AUTOSAR XML (schema 00046)
standard types defined: uint16, uint32, uint8, boolean
package /Constants
  14 x constant specification:
    Init_OnOffNull2: value-spec=0
    Init_ReducedGuardDStat: value-spec=0
    Init_RequestStatusType: value-spec=0
    Init_TrnNtrlTowCmdActl: value-spec=0
    InitVal_doorAjarStatus: value-spec=[Index_0:DoorAjarStatus_AJAR, Index_1:DoorAjarStatus_AJAR, Index_2:DoorAjarStatus_AJAR, Index_3:DoorAjarStatus_AJAR, Index_4:DoorAjarStatus_AJAR, Index_5:DoorAjarStatus_AJAR, Index_6:DoorAjarStatus_AJAR, Index_7:DoorAjarStatus_AJAR, Index_8:DoorAjarStatus_AJAR, Index_9:DoorAjarStatus_AJAR]
    InitVal_exteriorDoorHandleStatus: value-spec=[index_0:ExteriorDoorHandleStatus_LOCK_STATUS_FAULTY, index_1:ExteriorDoorHandleStatus_LOCK_STATUS_FAULTY, index_2:ExteriorDoorHandleStatus_LOCK_STATUS_FAULTY, index_3:ExteriorDoorHandleStatus_LOCK_STATUS_FAULTY, index_4:ExteriorDoorHandleStatus_LOCK_STATUS_FAULTY, index_5:ExteriorDoorHandleStatus_LOCK_STATUS_FAULTY, index_6:ExteriorDoorHandleStatus_LOCK_STATUS_FAULTY, index_7:ExteriorDoorHandleStatus_LOCK_STATUS_FAULTY, index_8:ExteriorDoorHandleStatus_LOCK_STATUS_FAULTY, index_9:ExteriorDoorHandleStatus_LOCK_STATUS_FAULTY]
    InitVal_exteriorLockEventCount: value-spec=1
    InitVal_exteriorVehicleLockStatus: value-spec=0
    InitVal_lastLockUnlockRequestor: value-spec=0
    InitVal_PerimeterAlrmStat: value-spec=0
    InitVal_VehPwMdeStatGrp: value-spec={short-label=InitVal_VehPwMdeStatGrp, fields=[VehPwMdeStat:VPM20, VehPwMdeStatQlfr:VehPwMdeStatQlfr_NO_DATA_EXISTS]}
    InitVal_VSUActvtyStat: value-spec=0
    InitVal_VSUInhbtStat: value-spec={short-label=InitVal_VSUInhbtStat, fields=VSUInhbtStat:VSUInhbtStat_VSU_NO_INHIBIT}
    InitValue_IntrusionInclinationStatus: value-spec=[fields=[SensorId:sensorIdEnum_INCLINATION, SensorState:SensorStateEnum_UNKNOWN, SensorModuleHealthStat:SensorModuleHealthEnum_NOT_AVAILABLE, SensorTriggeredData:SensorTriggeredDataEnum_NOT_TRIGGERED], fields=[SensorId:sensorIdEnum_INTRUSION, SensorState:SensorStateEnum_UNKNOWN, SensorModuleHealthStat:SensorModuleHealthEnum_NOT_AVAILABLE, SensorTriggeredData:SensorTriggeredDataEnum_NOT_TRIGGERED]]
package /DataConstraints
  range boolean_DataConstr6: raw 0..1
package /DataTypeMappings
  7 x data type mapping set:
    DataTypeMappingSet_AutoVehicleShutdownServiceProvider
      data-type-maps:
        application-data-type=AVSConfigType, implementation-data-type=uint8
        application-data-type=AVSShutdownLimitInfo, implementation-data-type=uint8
        application-data-type=AVSWarningInfo, implementation-data-type=uint8
        application-data-type=FeatureID, implementation-data-type=uint8
        application-data-type=IdleShutdownTimeRange, implementation-data-type=uint8
        application-data-type=InhibitRequestType, implementation-data-type=uint8
        application-data-type=InhibitStatus, implementation-data-type=uint8
        application-data-type=RequestStatusType, implementation-data-type=uint8
        application-data-type=UserSelRange, implementation-data-type=uint16
        application-data-type=boolean, implementation-data-type=boolean
    DataTypeMappingSet_DoorService
      data-type-maps:
        application-data-type=AnyDoorAjarStatusEnum, implementation-data-type=uint8
        application-data-type=AudibleLockFeedbackEnum, implementation-data-type=uint8
        application-data-type=DoorAjarStatusArray, implementation-data-type=DoorAjarStatusArray
        application-data-type=DoorCinchStatusArray, implementation-data-type=DoorCinchStatusArray
        application-data-type=DoorFullOpenStatusArray, implementation-data-type=DoorFullOpenStatusArray
        application-data-type=DoorIDBF, implementation-data-type=uint16
        application-data-type=DoorOffStatusArray, implementation-data-type=DoorOffStatusArray
        application-data-type=DoorOpenOperationStatusArray, implementation-data-type=DoorOpenOperationStatusArray
        application-data-type=DoorServiceCapabilityArray, implementation-data-type=DoorServiceCapabilityArray
        application-data-type=EmergencyReleaseSwitchStatusEnum, implementation-data-type=uint8
        application-data-type=ExteriorDoorHandleButtonStatusArray, implementation-data-type=ExteriorDoorHandleButtonStatusArray
        application-data-type=ExteriorDoorHandleStatusArray, implementation-data-type=ExteriorDoorHandleStatusArray
        application-data-type=ExteriorSideDoorCloseLockSwitchStatusArray, implementation-data-type=ExteriorSideDoorCloseLockSwitchStatusArray
        application-data-type=ExteriorSideDoorUnlockReleaseSwitchStatusArray, implementation-data-type=ExteriorSideDoorUnlockReleaseSwitchStatusArray
        application-data-type=ExteriorVehicleLockStatusEnum, implementation-data-type=uint8
        application-data-type=FrunkLatchCommandRequestEnum, implementation-data-type=uint8
        application-data-type=FrunkLatchMotorFaultStatusEnum, implementation-data-type=uint8
        application-data-type=FrunkLatchMotorStatusEnum, implementation-data-type=uint8
        application-data-type=HoodAjarSwitchStatusEnum, implementation-data-type=uint8
        application-data-type=Integer, implementation-data-type=uint8
        application-data-type=InteriorDoorHandleButtonStatusArray, implementation-data-type=InteriorDoorHandleButtonStatusArray
        application-data-type=InteriorDoorHandleStatusArray, implementation-data-type=InteriorDoorHandleStatusArray
        application-data-type=InteriorSideDoorReleaseSwitchStatusArray, implementation-data-type=InteriorSideDoorReleaseSwitchStatusArray
        application-data-type=LatchPositionStatusArray, implementation-data-type=LatchPositionStatusArray
        application-data-type=LockoutProtectionClassEnum, implementation-data-type=uint8
        application-data-type=OneTwoStageBehaviourEnum, implementation-data-type=uint8
        application-data-type=OpenCloseCustomizationStatusArray, implementation-data-type=OpenCloseCustomizationStatusArray
        application-data-type=OverrideAllowedEnum, implementation-data-type=uint8
        application-data-type=PawlSwitchStatusEnum, implementation-data-type=uint8
        application-data-type=ReleaseSwitchStatusEnum, implementation-data-type=uint8
        application-data-type=RequestorTypeClassEnum, implementation-data-type=uint8
        application-data-type=RequestorTypeClassMEnum, implementation-data-type=uint8
        application-data-type=SideDoorSwitchStatusEnum, implementation-data-type=uint8
        application-data-type=TrimInhibitSettingEnum, implementation-data-type=uint8
        application-data-type=TrimSwitchInhibitStatusEnum, implementation-data-type=uint8
        application-data-type=VehicleAreaEnum, implementation-data-type=uint8
    DataTypeMappingSet_IntrusionInclinationServiceProvider
      data-type-maps:
        application-data-type=AlarmState, implementation-data-type=uint8
        application-data-type=CSMTestRequest, implementation-data-type=uint8
        application-data-type=ConfigStatus, implementation-data-type=uint8
        application-data-type=FaultValue, implementation-data-type=uint8
        application-data-type=IntrusionInclinationCapabilityArr, implementation-data-type=IntrusionInclinationCapabilityArr
        application-data-type=IntrusionInclinationIdEnum, implementation-data-type=uint8
        application-data-type=IntrusionInclinationStatusArr, implementation-data-type=IntrusionInclinationStatusArr
        application-data-type=ModeIdEnum, implementation-data-type=uint8
        application-data-type=RearIntrusionStatusStrct, implementation-data-type=RearIntrusionStatusStrct
        application-data-type=SelfTestState, implementation-data-type=uint8
        application-data-type=SensorControlRequest, implementation-data-type=uint8
        application-data-type=SensorModuleHealthEnum, implementation-data-type=uint8
        application-data-type=SensorState, implementation-data-type=uint8
        application-data-type=SensorStateEnum, implementation-data-type=uint8
        application-data-type=SensorTriggeredDataEnum, implementation-data-type=uint8
    DataTypeMappingSet_PerimeterAntiTheftAlarmFeatureApp
      data-type-maps:
        application-data-type=OnOffNull2, implementation-data-type=uint8
        application-data-type=PerimeterAlrmStat, implementation-data-type=uint8
        application-data-type=PrmtrAlrmEvntDStat2, implementation-data-type=uint8
        application-data-type=ReducedGuard, implementation-data-type=uint8
        application-data-type=TrnNtrlTowCmdActl, implementation-data-type=uint8
        application-data-type=VSUActvtyStat, implementation-data-type=uint8
    DataTypeMappingSet_PerimeterAntiTheftAlarmFeatureAppASILB
      data-type-maps:
        application-data-type=VSUInhbtStat, implementation-data-type=VSUInhbtStat
        application-data-type=VSUInhbtStatType, implementation-data-type=uint8
    DataTypeMappingSet_SounderServiceProvider
      data-type-maps:
        application-data-type=HornPatternEnum, implementation-data-type=uint8
        application-data-type=HornStatusEnum, implementation-data-type=uint8
        application-data-type=Repetitions, implementation-data-type=uint16
        application-data-type=SoundPatternEnum, implementation-data-type=uint8
        application-data-type=SounderIdEnum, implementation-data-type=uint8
        application-data-type=SounderRequestEnum, implementation-data-type=uint8
        application-data-type=SounderStatusArr, implementation-data-type=SounderStatusArr
        application-data-type=Time, implementation-data-type=uint16
        application-data-type=customTimeConfigStrct, implementation-data-type=customTimeConfigStrct
        application-data-type=uint16, implementation-data-type=uint16
        application-data-type=uint32, implementation-data-type=uint32
        application-data-type=uint8, implementation-data-type=uint8
    DataTypeMappingSet_TurnLightServiceProvider
      data-type-maps:
        application-data-type=AllFlashActn, implementation-data-type=uint8
        application-data-type=ExteriorLightActuationStatus, implementation-data-type=uint8
        application-data-type=ExteriorLightHealth, implementation-data-type=uint8
        application-data-type=ExteriorLightOnOff, implementation-data-type=uint8
        application-data-type=ExteriorLightPositionEnum, implementation-data-type=uint8
        application-data-type=ExteriorLightPurposeEnum, implementation-data-type=uint8
        application-data-type=ExteriorLightStatus, implementation-data-type=uint8
        application-data-type=ExtrLghtMs, implementation-data-type=uint16
        application-data-type=ExtrLightActionFlash, implementation-data-type=uint8
        application-data-type=FlashPatternEnum, implementation-data-type=uint8
        application-data-type=FlashTSrc, implementation-data-type=uint8
        application-data-type=GlobalStartTime, implementation-data-type=GlobalStartTime
        application-data-type=HazrdLghtStat, implementation-data-type=uint8
        application-data-type=Integer, implementation-data-type=uint8
        application-data-type=Intensity_Adt, implementation-data-type=uint8
        application-data-type=LeFlashActn, implementation-data-type=uint8
        application-data-type=LifeCycMdeDActl, implementation-data-type=uint8
        application-data-type=LightPositionEnum, implementation-data-type=uint8
        application-data-type=LightPurposeEnum, implementation-data-type=uint8
        application-data-type=Priority, implementation-data-type=uint16
        application-data-type=RiFlashActn, implementation-data-type=uint8
        application-data-type=StartTime_Adt, implementation-data-type=uint32
        application-data-type=TellTaleActStrct, implementation-data-type=TellTaleActStrct
        application-data-type=TellTaleId, implementation-data-type=uint8
        application-data-type=TurnDirectionEnum, implementation-data-type=uint8
        application-data-type=TurnIndcnStat, implementation-data-type=uint8
        application-data-type=TurnLightIdEnum, implementation-data-type=uint8
        application-data-type=TurnLightStatusArray, implementation-data-type=TurnLightStatusArray
        application-data-type=VehPwMdeStat, implementation-data-type=uint8
        application-data-type=VehPwMdeStatGrp, implementation-data-type=VehPwMdeStatGrp
        application-data-type=VehPwMdeStatQlfrEnum, implementation-data-type=uint8
        application-data-type=WarningTypeEnum, implementation-data-type=uint8
        application-data-type=boolean, implementation-data-type=boolean
        application-data-type=exteriorLightOnOffFadeEnum, implementation-data-type=uint8
        application-data-type=exteriorLightStatusStrct, implementation-data-type=exteriorLightStatusStrct
package /DataTypeMappingSets
  7 x data type mapping set:
    DataTypeMappingSet_StrtUpStopArbitrator
      data-type-maps:
        application-data-type=AcsyDlyStat, implementation-data-type=uint8
        application-data-type=StrtRqTypeStat, implementation-data-type=uint8
    DataTypeMappingSet_TrailerAlarmServiceConsumer
      data-type-maps:
        application-data-type=TrailerAlarmActivation, implementation-data-type=uint8
        application-data-type=TrailerAlarmFault, implementation-data-type=uint8
        application-data-type=TrailerAlarmTimer, implementation-data-type=uint8
        application-data-type=TrailerAlarmTrigger, implementation-data-type=uint8
    DataTypeMappingSet_TrailerAlarmServiceProvider
      data-type-maps:
        application-data-type=TrailerAlarmActivation, implementation-data-type=uint8
        application-data-type=TrailerAlarmFault, implementation-data-type=uint8
        application-data-type=TrailerAlarmTimer, implementation-data-type=uint8
        application-data-type=TrailerAlarmTrigger, implementation-data-type=uint8
    DataTypeMappingSet_TrailerConnectionAlarmServiceProvider: data-type-map{application-data-type=TrailerConnectionAlarmSetting, implementation-data-type=uint8}
    PerimeterAlrmVehMdeNewTrgEvnt
      data-type-maps:
        application-data-type=Duration, implementation-data-type=uint32
        application-data-type=LifeCycMdeDActl, implementation-data-type=uint8
        application-data-type=PerimeterAlarmEvStackArray, implementation-data-type=PerimeterAlarmEvStackArray
        application-data-type=PerimeterAlarmTmStackArray, implementation-data-type=PerimeterAlarmTmStackArray
        application-data-type=UseCaseId, implementation-data-type=uint32
        application-data-type=DoorAjarStatusEnum, implementation-data-type=uint8
        application-data-type=ExteriorDoorHandleStatusEnum, implementation-data-type=uint8
        application-data-type=SensorIdEnum, implementation-data-type=uint8
        application-data-type=SensorModuleHealthEnum, implementation-data-type=uint8
        application-data-type=SensorStateEnum, implementation-data-type=uint8
        application-data-type=SensorTriggeredDataEnum, implementation-data-type=uint8
        application-data-type=ClimateAirflwSettingArr, implementation-data-type=ClimateAirflwSettingArr
        application-data-type=ClimateAirflwSettingStrct, implementation-data-type=ClimateAirflwSettingStrct
        application-data-type=ClimtZnId, implementation-data-type=uint8
        application-data-type=Spprtd, implementation-data-type=boolean
        application-data-type=ClimtMdeStat, implementation-data-type=boolean
        application-data-type=ClimtSpdLvl, implementation-data-type=uint8
        application-data-type=TrailerConnection, implementation-data-type=uint8
    SounderSrvc
      data-type-maps:
        application-data-type=HornPatternEnum, implementation-data-type=uint8
        application-data-type=HornStatusEnum, implementation-data-type=uint8
        application-data-type=Repetitions, implementation-data-type=uint16
        application-data-type=SoundPatternEnum, implementation-data-type=uint8
        application-data-type=SounderActuationStatusEnum, implementation-data-type=uint8
        application-data-type=SounderHealthEnum, implementation-data-type=uint8
        application-data-type=SounderIdEnum, implementation-data-type=uint8
        application-data-type=SounderStatusArr, implementation-data-type=SounderStatusArr
        application-data-type=SounderStatusStrct, implementation-data-type=SounderStatusStrct
        application-data-type=Time, implementation-data-type=uint16
        application-data-type=boolean, implementation-data-type=boolean
        application-data-type=customTimeConfigStrct, implementation-data-type=customTimeConfigStrct
        application-data-type=uint8, implementation-data-type=uint8
        application-data-type=uint16, implementation-data-type=uint16
        application-data-type=uint32, implementation-data-type=uint32
        application-data-type=SounderRequestEnum, implementation-data-type=uint8
    Timer: data-type-map{application-data-type=TmrCntUnit32, implementation-data-type=uint32}
package /DataTypes
  4 x impl type, all with category=VALUE, base-type=uint8, sw-calibration-access=READ-ONLY, type-emitter=RTE:
    AlarmSoundCfg: compu {0=VEHICLE_HORN, 1=SECURITY_HORN, 2=BBS, 3=BBS_VEHICLE_HORN}
    PerimeterAlrmStat: compu-method=PerimeterAlrmStat, range raw 0..3
    ReducedGuard: compu-method=ReducedGuard, range raw 0..3
    SecurityCfg: compu {0=SECURITYCFG_NONE, 1=SECURITYCFG_BOTH, 2=SECURITYCFG_INCLINATION, 3=SECURITYCFG_INTRUSION, 4=SECURITYCFG_INTRUSION_REAR_INTRUSION, 5=SECURITYCFG_BOTH_REAR_INTRUSION}, range raw 0..5
package /DataTypes/ApplicationDataTypes
  22 x application array data type, all with category=ARRAY:
    ClimateAirflwSettingArr
      element ClimateAirflwSettingArr: category=STRUCTURE, type=ClimateAirflwSettingStrct, array-size-semantics=FIXED-SIZE, max-number-of-elements=19
    DoorAjarStatusArray
      element DoorAjarStatusArray: category=VALUE, type=DoorAjarStatusEnum, array-size-semantics=FIXED-SIZE, max-number-of-elements=10
    DoorCinchStatusArray
      element DoorCinchStatusArray: category=VALUE, type=DoorCinchStatusEnum, array-size-semantics=FIXED-SIZE, max-number-of-elements=10
    DoorFullOpenStatusArray
      element DoorFullOpenStatusArray: category=VALUE, type=DoorFullOpenStatusEnum, array-size-semantics=FIXED-SIZE, max-number-of-elements=10
    DoorOffStatusArray
      element DoorOffStatusArray: category=VALUE, type=DoorOffStatusEnum, array-size-semantics=FIXED-SIZE, max-number-of-elements=10
    DoorOpenOperationStatusArray
      element DoorOpenOperationStatusArray: category=VALUE, type=DoorOpenOperationStatusEnum, array-size-semantics=FIXED-SIZE, max-number-of-elements=10
    DoorServiceCapabilityArray
      element DoorServiceCapabilityArray: category=VALUE, type=DoorServiceCapabilityStatusBF, array-size-semantics=FIXED-SIZE, max-number-of-elements=10
    ExteriorDoorHandleButtonStatusArray
      element ExteriorDoorHandleButtonStatusArray: category=VALUE, type=SideDoorSwitchStatusEnum, array-size-semantics=FIXED-SIZE, max-number-of-elements=10
    ExteriorDoorHandleStatusArray
      element ExteriorDoorHandleStatusArray: category=VALUE, type=ExteriorDoorHandleStatusEnum, array-size-semantics=FIXED-SIZE, max-number-of-elements=10
    ExteriorSideDoorCloseLockSwitchStatusArray
      element ExteriorSideDoorCloseLockSwitchStatusArray: category=VALUE, type=SideDoorSwitchStatusEnum, array-size-semantics=FIXED-SIZE, max-number-of-elements=6
    ExteriorSideDoorUnlockReleaseSwitchStatusArray
      element ExteriorSideDoorUnlockReleaseSwitchStatusArray: category=VALUE, type=SideDoorSwitchStatusEnum, array-size-semantics=FIXED-SIZE, max-number-of-elements=6
    InteriorDoorHandleButtonStatusArray
      element InteriorDoorHandleButtonStatusArray: category=VALUE, type=SideDoorSwitchStatusEnum, array-size-semantics=FIXED-SIZE, max-number-of-elements=10
    InteriorDoorHandleStatusArray
      element InteriorDoorHandleStatusArray: category=VALUE, type=InteriorDoorHandleStatusEnum, array-size-semantics=FIXED-SIZE, max-number-of-elements=10
    InteriorSideDoorReleaseSwitchStatusArray
      element InteriorSideDoorReleaseSwitchStatusArray: category=VALUE, type=SideDoorSwitchStatusEnum, array-size-semantics=FIXED-SIZE, max-number-of-elements=6
    IntrusionInclinationCapabilityArr
      element IntrusionInclinationCapabilityArr: category=VALUE, type=IntrusionInclinationCapabilityStrct, array-size-semantics=FIXED-SIZE, max-number-of-elements=4
    IntrusionInclinationStatusArr
      element IntrusionInclinationStatusArr: category=VALUE, type=IntrusionInclinationStatusStrct, array-size-semantics=FIXED-SIZE, max-number-of-elements=2
    LatchPositionStatusArray
      element LatchPositionStatusArray: category=VALUE, type=LatchPositionEnum, array-size-semantics=FIXED-SIZE, max-number-of-elements=10
    OpenCloseCustomizationStatusArray
      element OpenCloseCustomizationStatusArray: category=VALUE, type=OpenCloseCustomizationStatusEnum, array-size-semantics=FIXED-SIZE, max-number-of-elements=10
    PerimeterAlarmEvStackArray
      element PerimeterAlarmEvStackArray: category=VALUE, type=PrmtrAlrmEvntDStat2, array-size-semantics=FIXED-SIZE, max-number-of-elements=4
    PerimeterAlarmTmStackArray
      element PerimeterAlarmTmStackArray: category=VALUE, type=uint32, array-size-semantics=FIXED-SIZE, max-number-of-elements=4
    SounderStatusArr
      element SounderStatusArr: category=VALUE, type=SounderStatusStrct, array-size-semantics=FIXED-SIZE, max-number-of-elements=4
    TurnLightStatusArray
      element TurnLightStatusArray: category=STRUCTURE, type=exteriorLightStatusStrct, array-size-semantics=FIXED-SIZE, max-number-of-elements=10
  116 x app type, all with category=VALUE:
    AcsyDlyStat: sw-calibration-access=READ-WRITE, compu {0=ACSYDLYSTAT_DELAYED_ACCESSORY_ACTIVE, 1=ACSYDLYSTAT_DELAYED_ACCESSORY_INACTIVE; unit SED}, range raw 0..1
    AlarmState: compu {0=AlarmState_ALARM_FALSE, 1=AlarmState_ALARM_TRUE, else 0}, range raw 0..1, unit=NoUnit
    AllFlashActn: compu {0=AllFlashActnEnum_OFF, 1=AllFlashActnEnum_ON}, range raw 0..1, unit=NoUnit
    AnyDoorAjarStatusEnum: sw-calibration-access=READ-WRITE, compu {0=AnyDoorAjarStatus_FAULTY, 1=AnyDoorAjarStatus_ANY_AJAR, 2=AnyDoorAjarStatus_ALL_CLOSED, 3=AnyDoorAjarStatus_UNKNOWN, 4=AnyDoorAjarStatus_NOT_AVAILABLE}, range raw 0..4, unit=NoUnit
    AudibleLockFeedbackEnum: compu {0=AudibleLockFeedback_LOCK_CONFIRMATION, 1=AudibleLockFeedback_MISLOCK, 2=AudibleLockFeedback_NONE}, range raw 0..2, unit=NoUnit
    AVSConfigType: compu {0=AVSConfigType_BEV, 1=AVSConfigTypee_NON_BEV, 2=AVSConfigType_DRIVER_SELECTABLE, 3=AVSConfigType_FLEET, 4..7=AVSConfigType_RESERVED_1..AVSConfigType_RESERVED_4, else 0}, range raw 0..7, unit=NoUnit
    AVSShutdownLimitInfo: compu {0=AVSShutdownLimitInfo_UNKNOWN, 1=AVSShutdownLimitInfo_NORMAL_OPERATION, 2=AVSShutdownLimitInfo_AVS_SHUTDOWN, 3=AVSShutdownLimitInfo_DELAY_SHUTDOWN_ACTIVE, 4=AVSShutdownLimitInfo_AVS_RANGE_SHUTDOWN_HANDSHAKE, 5=AVSShutdownLimitInfo_AVS_PPA_SHUTDOWN, 6=AVSShutdownLimitInfo_AVS_RANGE_SHUTDOWN, else 0}, range raw 0..6, unit=NoUnit
    AVSWarningInfo:
      compu {0=AVSWarningInfo_DEFAULT, 1=AVSWarningInfo_RRC_5MILE_WARNING, 2=AVSWarningInfo_RRC_2MILE_WARNING, 3=AVSWarningInfo_30SECOND_WARNING_TIMER, 4=AVSWarningInfo_POWERTRAIN_OFF, 5=AVSWarningInfo_30SECOND_WARNING_RANGE, 6=AVSWarningInfo_TIMER_DISABLED, 7=AVSWarningInfo_RANGE_DISABLED, 8=AVSWarningInfo_ADES_DISABLED, 9=AVSWarningInfo_AVS_DISABLED, 10..13=AVSWarningInfo_AVS_RESERVED_1..AVSWarningInfo_AVS_RESERVED_4, else 0}
      range raw 0..13
      unit=NoUnit
    boolean: compu {0=FALSE, 1=TRUE}, range raw 0..1, unit=NoUnit
    ClimtMdeStat: compu {0=CLIMTMDESTATENUM_MANUAL, 1=CLIMTMDESTATENUM_AUTO}, range raw 0..1, unit=NoUnit
    ClimtSpdLvl: compu {phys=raw for raw 0..100}, range phys 0..100, unit=NoUnit
    ClimtZnId:
      compu {0=CLIMATEROW1LEFT, 1=CLIMATEROW1RIGHT, 2=CLIMATEROW2LEFT, 3=CLIMATEROW2RIGHT, 4=CLIMATEROW3LEFT, 5=CLIMATEROW3RIGHT, 6=CLIMATEROW1GROUP, 7=CLIMATEROW2GROUP, 8=CLIMATEROW3GROUP, 9=CLIMATELEFTREARGROUP, 10=CLIMATERIGHTREARGROUP, 11=CLIMATEALLREARGROUP, 12=CLIMATEFRUNK, 13=CLIMATECONSOLE, 14=CLIMATETRUNK, 15=CLIMATEROW1CENTER, 16=CLIMATEROW2CENTER, 17=CLIMATEROW3CENTER, 18=CLIMATEALLGROUP}
      range raw 0..18
      unit=NoUnit
    ConfigStatus: compu {0=ConfigStatus_NO_CONFIG, 1=ConfigStatus_CONFIG, else 0}, range raw 0..1, unit=NoUnit
    CSMTestRequest: compu {0=CSMTestRequest_TEST_FALSE, 1=CSMTestRequest_TEST_TRUE, else 0}, range raw 0..1, unit=NoUnit
    DoorAjarStatusEnum: sw-calibration-access=READ-WRITE, compu {0=DoorAjarStatus_CLOSED, 1=DoorAjarStatus_AJAR, 2=DoorAjarStatus_FAULTY, 3=DoorAjarStatus_UNKNOWN, 4=DoorAjarStatus_NOT_AVAILABLE}, range raw 0..4, unit=NoUnit
    DoorCinchStatusEnum: sw-calibration-access=READ-WRITE, compu {0=DoorCinchStatus_NULL, 1=DoorCinchStatus_IN_PROGRESS, 2=DoorCinchStatus_FAULTY, 3=DoorCinchStatus_UNKNOWN, 4=DoorCinchStatus_NOT_AVAILABLE}, range raw 0..4, unit=NoUnit
    DoorFullOpenStatusEnum: sw-calibration-access=READ-WRITE, compu {0=DoorFullOpenStatus_CLOSED, 1=DoorFullOpenStatus_PARTIALLY_OPEN, 2=DoorFullOpenStatus_FAULTY, 3=DoorFullOpenStatus_NOT_AVAILABLE, 4=DoorFullOpenStatus_FULLY_OPEN}, range raw 0..4, unit=NoUnit
    DoorIDBF: sw-calibration-access=READ-WRITE, compu {phys=raw for raw 0..1023, 1=DoorIDBF_DRIVER, 128=DoorIDBF_DRIVER_THIRD_ROW, 16=DoorIDBF_BEC, 2=DoorIDBF_PASSENGER, 256=DoorIDBF_PASSENGER_THIRD_ROW, 32=DoorIDBF_BEC2, 4=DoorIDBF_DRIVER_SECOND_ROW, 512=DoorIDBF_BEC3, 64=DoorIDBF_FEC, 8=DoorIDBF_PASSENGER_SECOND_ROW}, range raw 0..1023, unit=NoUnit
    DoorOffStatusEnum: sw-calibration-access=READ-WRITE, compu {0=DoorOffStatus_MOUNTED, 1=DoorOffStatus_NOT_MOUNTED, 2=DoorOffStatus_FAULTY, 3=DoorOffStatus_NOT_DETERMINED}, range raw 0..3, unit=NoUnit
    DoorOpenOperationStatusEnum: sw-calibration-access=READ-WRITE, compu {0=DoorOpenOperationStatus_NOT_MOVING, 1=DoorOpenOperationStatus_OPENING, 2=DoorOpenOperationStatus_CLOSING, 3=DoorOpenOperationStatus_OBSTACLE_DETECTED}, range raw 0..3, unit=NoUnit
    DoorServiceCapabilityStatusBF:
      sw-calibration-access=READ-WRITE
      compu {phys=raw for raw 0..127, 1=DoorServiceCapabilityStatus_EXISTS, 16=DoorServiceCapabilityStatus_POWER_RELEASABLE, 2=DoorServiceCapabilityStatus_EXT_LOCKABLE_UNLOCKABLE, 32=DoorServiceCapabilityStatus_DOOR_REMOVABLE_BY_USER, 4=DoorServiceCapabilityStatus_INT_LOCKABLE_UNLOCKABLE, 64=DoorServiceCapabilityStatus_CARGO_DOOR, 8=DoorServiceCapabilityStatus_POWER_OPENABLE_CLOSEABLE}
      range raw 0..127
      unit=NoUnit
    Duration: compu {phys=raw for raw 0..4294967295}, range raw 0..4294967295, unit=NoUnit
    EmergencyReleaseSwitchStatusEnum: compu {0=EmergencyReleaseSwitchStatus_UNKNOWN, 1=EmergencyReleaseSwitchStatus_INACTIVE, 2=EmergencyReleaseSwitchStatus_ACTIVE, 3=EmergencyReleaseSwitchStatus_FAULT_VOLTAGE, 4=EmergencyReleaseSwitchStatus_FAULT_UNSTABLE, 5=EmergencyReleaseSwitchStatus_FAULT_SHORT_TO_GROUND, 6=EmergencyReleaseSwitchStatus_FAULT_SHORT_TO_BATTERY, 7=EmergencyReleaseSwitchStatus_STUCK}, range raw 0..7, unit=NoUnit
    ExteriorDoorHandleStatusEnum: sw-calibration-access=READ-WRITE, compu {0=ExteriorDoorHandleStatus_LOCKED, 1=ExteriorDoorHandleStatus_UNLOCKED, 2=ExteriorDoorHandleStatus_LOCK_STATUS_NOT_AVAILABLE, 3=ExteriorDoorHandleStatus_LOCK_STATUS_FAULTY}, range raw 0..3, unit=NoUnit
    ExteriorLightActuationStatus: compu {0=ExteriorLightActuationStatus_OFF, 1=ExteriorLightActuationStatus_ON, 2=ExteriorLightActuationStatus_FLASHING, 3=ExteriorLightActuationStatus_FADING_UP, 4=ExteriorLightActuationStatus_FADING_DOWN, 5=ExteriorLightActuationStatus_NOT_AVAILABLE}, range raw 0..5, unit=NoUnit
    ExteriorLightHealth: compu {0=ExteriorLightHealth_OK, 1=ExteriorLightHealth_NOT_OK, 2=ExteriorLightHealth_UNKNOWN}, range raw 0..2, unit=NoUnit
    ExteriorLightOnOff: compu {0=ExteriorLightOnOff_OFF, 1=ExteriorLightOnOff_ON}, range raw 0..1, unit=NoUnit
    exteriorLightOnOffFadeEnum: compu {0=LightAction_OFF, 1=LightAction_ON, 2=LightAction_FADE}, range raw 0..2, unit=NoUnit
    ExteriorLightPositionEnum: compu-method=LightPositionEnum, range raw 0..21, unit=NoUnit
    ExteriorLightPurposeEnum: compu-method=LightPurposeEnum, range raw 0..31, unit=NoUnit
    ExteriorLightStatus: compu {0=EXTLIGHTSTATUS_LIGHT_ON, 1=EXTLIGHTSTATUS_LIGHT_OFF, 2=EXTLIGHTSTATUS_LIGHT_FLASHING, 3=EXTLIGHTSTATUS_LIGHT_FADING_UP, 4=EXTLIGHTSTATUS_LIGHT_FADING_DOWN, 5=EXTLIGHTSTATUS_LIGHT_OUTAGE, 6=EXTLIGHTSTATUS_LIGHT_FAULT, 7=EXTLIGHTSTATUS_LIGHT_NOT_AVAILABLE}, range raw 0..7, unit=NoUnit
    ExteriorVehicleLockStatusEnum: sw-calibration-access=READ-WRITE, compu {0=ExteriorVehicleLockStatus_CENTRALLY_LOCKED, 1=ExteriorVehicleLockStatus_CENTRALLY_UNLOCKED, 2=ExteriorVehicleLockStatus_PARTIALLY_LOCKED}, range raw 0..2, unit=NoUnit
    ExtrLghtMs: compu {phys=raw*10 for raw 0..1000; unit ms}, range raw 0..9999, unit=ms
    ExtrLightActionFlash: compu {0=FlashAction_DISABLE, 1=FlashAction_ENABLE}, range raw 0..1, unit=NoUnit
    FaultValue: compu {0=FaultValue_NORMAL, 1=FaultValue_FAULTY, else 0}, range raw 0..1, unit=NoUnit
    FeatureID:
      compu {0=FeatureID_DEFAULT, 1=FeatureID_UPFITTER, 2=FeatureID_POLICE_IDLE, 3=FeatureID_AMBULANCE, 4=FeatureID_HMI, 5=FeatureID_PRO_TRAILER_HITCH_ASSISTANT, 6=FeatureID_PPO, 7=FeatureID_DELIVERY_ASSIST, 8=FeatureID_BI_DIRECTIONAL_POWER, 9=FeatureID_CLIMATE_CONTROL_FUNK, 10=FeatureID_CABIN_CONDITIONING, 11=FeatureID_INFINITE_TIMER, 12=FeatureID_CHARGING, 13=FeatureID_DISABLE_AVS, 14=FeatureID_FACTORY_MODE, 15=FeatureID_TRANSPORT_MODE, 16..20=FeatureID_RESERVED_1..FeatureID_RESERVED_5, else 0}
      range raw 0..20
      unit=NoUnit
    FlashPatternEnum: compu {0=FlashPatternEnum_SINGLE_FLASH, 1=FlashPatternEnum_DOUBLE_FLASH, 2=FlashPatternEnum_TRIPLE_FLASH, 3=FlashPatternEnum_LONG_SINGLE_FLASH, 4=FlashPatternEnum_CUSTOM}, range raw 0..4, unit=NoUnit
    FlashTSrc: compu {0=FlashTSrc_FLASH_T_PARAMETERS, 1=FlashTSrc_TURNINDCRLET, 2=FlashTSrc_TURNINDCRRIT, 3=FlashTSrc_TURNINDCRALLT}, range raw 0..3, unit=NoUnit
    FrunkLatchCommandRequestEnum: compu {0=FrunkLatchCommandRequest_HALT, 1=FrunkLatchCommandRequest_CINCH, 2=FrunkLatchCommandRequest_SINGLE_RELEASE, 3=FrunkLatchCommandRequest_DOUBLE_RELEASE, 4=FrunkLatchCommandRequest_HOME}, range raw 0..4, unit=NoUnit
    FrunkLatchMotorFaultStatusEnum: compu {0=FrunkLatchMotorFaultStatus_NO_FAULT, 1=FrunkLatchMotorFaultStatus_FAULT}, range raw 0..1, unit=NoUnit
    FrunkLatchMotorStatusEnum: compu {0=FrunkLatchMotorStatus_INACTIVE, 1=FrunkLatchMotorStatus_CINCH_IN_PROGRESS, 2=FrunkLatchMotorStatus_RELEASE_IN_PROGRESS, 3=FrunkLatchMotorStatus_HOME_IN_PROGRESS, 4=FrunkLatchMotorStatus_CINCH_COMPLETE, 5=FrunkLatchMotorStatus_RELEASE_COMPLETE, 6=FrunkLatchMotorStatus_HOME_COMPLETE}, range raw 0..6, unit=NoUnit
    HazrdLghtStat: compu {0=HazrdLghtStatEnum_OFF, 1=HazrdLghtStatEnum_ON}, range raw 0..1, unit=NoUnit
    HoodAjarSwitchStatusEnum: sw-calibration-access=READ-WRITE, compu {0=HoodAjarSwitchStatus_UNKNOWN, 1=HoodAjarSwitchStatus_INACTIVE, 2=HoodAjarSwitchStatus_ACTIVE, 3=HoodAjarSwitchStatus_FAULT_VOLTAGE, 4=HoodAjarSwitchStatus_FAULT_UNSTABLE, 5=HoodAjarSwitchStatus_FAULT_SHORT_TO_GROUND, 6=HoodAjarSwitchStatus_FAULT_SHORT_TO_BATTERY}, range raw 0..6, unit=NoUnit
    HornPatternEnum: compu {0=HornPatternEnum_CHIRP_1, 1=HornPatternEnum_CHIRP_2, 2=HornPatternEnum_CHIRP_3, 3=HornPatternEnum_CHIRPHONK, 4=HornPatternEnum_CHIRP_2H, 5=HornPatternEnum_PERIMETER_ALARM1_H, 6=HornPatternEnum_PERIMETER_ALARM2_H, 7=HornPatternEnum_HONK, 8=HornPatternEnum_POST_CRASH, 9=HornPatternEnum_PANIC_ALARM1, 10=HornPatternEnum_PANIC_ALARM2, 11=HornPatternEnum_OFF, else 0}, range raw 0..11, unit=NoUnit
    HornStatusEnum: compu {0=HornStatus_IDLE, 1=HornStatus_BUSY, 2=HornStatus_ERROR, 3=HornStatus_PAUSE, else 0}, range raw 0..3, unit=NoUnit
    IdleShutdownTimeRange: compu {phys=raw for raw 0..255; unit km}, range raw 0..255, unit=km
    InhibitRequestType:
      compu {0=InhibitRequestType_DEFAULT, 1=InhibitRequestType_START_TIMER_INHIBITED, 2=InhibitRequestType_TIMER_INHIBITED_PERMANENTLY, 3=InhibitRequestType_END_TIMER_INHIBITED, 4=InhibitRequestType_START_RANGE_INHIBITED, 5=InhibitRequestType_RANGE_INHIBITED_PERMANENTLY, 6=InhibitRequestType_END_RANGE_INHIBITED, 7=InhibitRequestType_START_ADES_INHIBITED, 8=InhibitRequestType_ADES_INHIBITED_PERMANENTLY, 9=InhibitRequestType_END_ADES_INHIBITED, 10=InhibitRequestType_START_DISABLE_DRIVER_EXIT_SHUTDOWN, 11=InhibitRequestType_DISABLE_DRIVER_EXIT_SHUTDOWN_PERMANENTLY, 12=InhibitRequestType_END_DISABLE_DRIVER_EXIT_SHUTDOWN, else 0}
      range raw 0..12
      unit=NoUnit
    InhibitStatus: compu {0=InhibitStatus_DEFAULT, 1=InhibitStatus_ACCEPTED, 2=InhibitStatus_PENDING, 3=InhibitStatus_REJECTED, 4=InhibitStatus_ERROR, else 0}, range raw 0..4, unit=NoUnit
    Integer: compu {phys=raw for raw 0..255; unit count}, range raw 0..255, unit=count
    Intensity_Adt: compu {phys=raw for raw 0..100; unit %}, range raw 0..100, unit=%
    InteriorDoorHandleStatusEnum: sw-calibration-access=READ-WRITE, compu {0=InteriorDoorHandleStatus_INT_LOCKED, 1=InteriorDoorHandleStatus_INT_UNLOCKED, 2=InteriorDoorHandleStatus_INT_LOCK_STATUS_NOT_AVAILABLE, 3=InteriorDoorHandleStatus_INT_LOCK_STATUS_FAULTY}, range raw 0..3, unit=NoUnit
    IntrusionInclinationIdEnum: compu {0=IntrusionInclinationIdEnum_CSM, 1=IntrusionInclinationIdEnum_REAR_INTRUSION, 2=IntrusionInclinationIdEnum_INCLINATION, 3=IntrusionInclinationIdEnum_INTRUSION, else 0}, range raw 0..3, unit=NoUnit
    LatchPositionEnum: sw-calibration-access=READ-WRITE, compu {0=LatchPosition_PRIMARY, 1=LatchPosition_SECONDARY, 2=LatchPosition_OPEN, 3=LatchPosition_UNKNOWN, 4=LatchPosition_NOT_AVAILABLE, 5=LatchPosition_FAULTY}, range raw 0..5, unit=NoUnit
    LeFlashActn: compu {0=LeFlashActnEnum_OFF, 1=LeFlashActnEnum_ON}, range raw 0..1, unit=NoUnit
    LifeCycMdeDActl:
      sw-calibration-access=READ-WRITE
      compu {0=LifeCycMdeDActl_NORMAL, 1=LifeCycMdeDActl_FACTORYFINISH, 2=LifeCycMdeDActl_NOTUSED2, 3=LifeCycMdeDActl_TRANSPORT, 4=LifeCycMdeDActl_NOTUSED4, 5=LifeCycMdeDActl_RECOMDECOM, 6=LifeCycMdeDActl_NOTUSED6, 7=LifeCycMdeDActl_FACTORYINPLANTFLASH, 8=LifeCycMdeDActl_FACTORYTESTSTATION, 9=LifeCycMdeDActl_FACTORYTRANSITION, 10..15=LifeCycMdeDActl_NOTUSED10..LifeCycMdeDActl_NOTUSED15}
      range raw 0..15
      unit=NoUnit
    LightPositionEnum: compu-method=LightPositionEnum, range raw 0..21, unit=NoUnit
    LightPurposeEnum: compu-method=LightPurposeEnum, range raw 0..31, unit=NoUnit
    LockoutProtectionClassEnum: sw-calibration-access=READ-WRITE, compu {0=LockoutProtectionClass_NO, 1=LockoutProtectionClass_YES}, range raw 0..1, unit=NoUnit
    ModeIdEnum: compu {0=ModeIdEnum_ARM, 1=ModeIdEnum_DISARM, else 0}, range raw 0..1, unit=NoUnit
    OneTwoStageBehaviourEnum: compu {0=OneTwoStageBehaviour_ONESTAGE, 1=OneTwoStageBehaviour_TWOSTAGE}, range raw 0..1, unit=NoUnit
    OnOffNull2: compu {0=OnOffNull2_NULL, 1=OnOffNull2_REQUEST_OFF, 2=OnOffNull2_REQUEST_ON, 3=OnOffNull2_REQUEST_PERSISTENT_ON, else 0}, range raw 0..3, unit=NoUnit
    OpenCloseCustomizationStatusEnum: sw-calibration-access=READ-WRITE, compu {0=OpenCloseCustomizationStatus_ENABLED, 1=OpenCloseCustomizationStatus_DISABLED}, range raw 0..1, unit=NoUnit
    OverrideAllowedEnum: compu {0=OverrideAllowed_NOT_ALLOWED, 1=OverrideAllowed_ALLOWED}, range raw 0..1, unit=NoUnit
    PawlSwitchStatusEnum: sw-calibration-access=READ-WRITE, compu {0=PawlSwitchStatus_UNKNOWN, 1=PawlSwitchStatus_INACTIVE, 2=PawlSwitchStatus_ACTIVE, 3=PawlSwitchStatus_FAULT_VOLTAGE, 4=PawlSwitchStatus_FAULT_UNSTABLE}, range raw 0..4, unit=NoUnit
    PerimeterAlrmStat: compu-method=PerimeterAlrmStat, range raw 0..3, unit=NoUnit
    Priority: compu {phys=raw for raw 0..9999}, range raw 0..9999, unit=NoUnit
    PrmtrAlrmEvntDStat2:
      compu {0=PrmtrAlrmEvntDStat2_NULL, 1=PrmtrAlrmEvntDStat2_DF_DOOR, 2=PrmtrAlrmEvntDStat2_PF_DOOR, 3=PrmtrAlrmEvntDStat2_DR_DOOR, 4=PrmtrAlrmEvntDStat2_PR_DOOR, 5=PrmtrAlrmEvntDStat2_LG_DOOR, 6=PrmtrAlrmEvntDStat2_CARGO_DOOR, 7=PrmtrAlrmEvntDStat2_DECKLID, 8=PrmtrAlrmEvntDStat2_HOOD, 9=PrmtrAlrmEvntDStat2_INCLINATION, 10=PrmtrAlrmEvntDStat2_INTRUSION, 11=PrmtrAlrmEvntDStat2_REAR_INTRUSION, 12=PrmtrAlrmEvntDStat2_TRAILER, 13=PrmtrAlrmEvntDStat2_DIAG_TAMPER, else 0}
      range raw 0..13
      unit=NoUnit
    ReducedGuard: compu-method=ReducedGuard, range raw 0..3, unit=NoUnit
    ReleaseSwitchStatusEnum: compu {0=ReleaseSwitchStatus_INACTIVE, 1=ReleaseSwitchStatus_ACTIVE, 2=ReleaseSwitchStatus_STUCK}, range raw 0..2, unit=NoUnit
    Repetitions: compu {phys=raw for raw 0..65535}, range raw 0..65535, unit=NoUnit
    RequestorTypeClassEnum: sw-calibration-access=READ-WRITE, compu {0=RequestorTypeClass_INTERIOR, 1=RequestorTypeClass_EXTERIOR, 2=RequestorTypeClass_CELLULAR, 3=RequestorTypeClass_REMOTE, 4=RequestorTypeClass_EMERGENCY, 5=RequestorTypeClass_WITHOUT_REQUEST}, range raw 0..5, unit=NoUnit
    RequestorTypeClassMEnum: compu {0=RequestorTypeClassM_INTERIOR, 1=RequestorTypeClassM_EXTERIOR, 2=RequestorTypeClassM_CELLULAR, 3=RequestorTypeClassM_REMOTE, 4=RequestorTypeClassM_EMERGENCY}, range raw 0..4, unit=NoUnit
    RequestStatusType: compu {0=RequestStatusType_DEFAULT, 1=RequestStatusType_CONFIRMED, 2=RequestStatusType_REJECTED, 3=RequestStatusType_ERROR, else 0}, range raw 0..3, unit=NoUnit
    RiFlashActn: compu {0=RiFlashActnEnum_OFF, 1=RiFlashActnEnum_ON}, range raw 0..1, unit=NoUnit
    SelfTestState: compu {0=SelfTestState_TEST_FALSE, 1=SelfTestState_IN_PROGRESS, 2=SelfTestState_SELFTEST_OK, 3=SelfTestState_SELFTEST_NOK, else 0}, range raw 0..3, unit=NoUnit
    SensorControlRequest: compu {0=SensorControlRequest_DISARM, 1=SensorControlRequest_ARM, else 0}, range raw 0..1, unit=NoUnit
    SensorIdEnum: compu {0=sensorIdEnum_INCLINATION, 1=sensorIdEnum_INTRUSION, else 0}, range raw 0..1, unit=NoUnit
    SensorModuleHealthEnum: compu {0=SensorModuleHealthEnum_OK, 1=SensorModuleHealthEnum_FAULT, 2=SensorModuleHealthEnum_NOT_CONFIGURED, 3=SensorModuleHealthEnum_NOT_AVAILABLE, 4=SensorModuleHealthEnum_LOST, else 0}, range raw 0..4, unit=NoUnit
    SensorState: compu {0=SensorState_DISARMED, 1=SensorState_ARMED, else 0}, range raw 0..1, unit=NoUnit
    SensorStateEnum: compu {0=SensorStateEnum_ARMED, 1=SensorStateEnum_DISARMED, 2=SensorStateEnum_UNKNOWN, else 0}, range raw 0..2, unit=NoUnit
    SensorTriggeredDataEnum: compu {0=SensorTriggeredDataEnum_TRIGGERED, 1=SensorTriggeredDataEnum_NOT_TRIGGERED, else 0}, range raw 0..1, unit=NoUnit
    SideDoorSwitchStatusEnum: compu {0=SideDoorSwitchStatus_NULL, 1=SideDoorSwitchStatus_PRESSED, 2=SideDoorSwitchStatus_FAULTY, 3=SideDoorSwitchStatus_NOT_AVAILABLE}, range raw 0..3, unit=NoUnit
    SounderActuationStatusEnum: compu {0=SounderActuationStatusEnum_OFF, 1=SounderActuationStatusEnum_ON, 2=SounderActuationStatusEnum_NOT_AVAILABLE, 3=SounderActuationStatusEnum_REP_DONE, 4=SounderActuationStatusEnum_ARM, 5=SounderActuationStatusEnum_DISARM, else 0}, range raw 0..5, unit=NoUnit
    SounderHealthEnum: compu {0=SounderHealthEnum_OK, 1=SounderHealthEnum_NOT_OK, 2=SounderHealthEnum_UNKNOWN, else 0}, range raw 0..2, unit=NoUnit
    SounderIdEnum: compu {0=SounderIdEnum_HORN, 1=SounderIdEnum_PIEZO, 2=SounderIdEnum_BATTERY_BACKED_SOUNDER, 3=SounderIdEnum_SECURITY_HORN, else 0}, range raw 0..3, unit=NoUnit
    SounderRequestEnum: compu {0=SoundRequestEnum_DEACTIVATE, 1=SoundRequestEnum_ACTIVATE, else 0}, range raw 0..1, unit=NoUnit
    SoundPatternEnum:
      compu {0=SoundPatternEnum_CHIRP_1, 1=SoundPatternEnum_CHIRP_2, 2=SoundPatternEnum_CHIRP_3, 3=SoundPatternEnum_CHIRPHONK, 4=SoundPatternEnum_CHIRP_2H, 5=SoundPatternEnum_BEEP_1, 6=SoundPatternEnum_BEEP_2, 7=SoundPatternEnum_RS_BEEP, 8=SoundPatternEnum_BEEP_OOA, 9=SoundPatternEnum_PERIMETER_ALARM1_H, 10=SoundPatternEnum_PERIMETER_ALARM2_H, 11=SoundPatternEnum_PERIMETER_ALARM1_SH, 12=SoundPatternEnum_PERIMETER_ALARM2_SH, 13=SoundPatternEnum_PERIMETER_ALARM1_BBS, 14=SoundPatternEnum_PERIMETER_ARMBBS, 15=SoundPatternEnum_PERIMETER_ALARM1_H_BBS, 16=SoundPatternEnum_PERIMETER_ALARM2_H_BBS, 17=SoundPatternEnum_HONK, 18=SoundPatternEnum_POST_CRASH, 19=SoundPatternEnum_PANIC_ALARM_1, 20=SoundPatternEnum_PANIC_ALARM_2, 21=SoundPatternEnum_OFF, else 0}
      range raw 0..21
      unit=NoUnit
    Spprtd: compu {0=SPPRTDENUM_UNSUPPORTED, 1=SPPRTDENUM_SUPPORTED}, range raw 0..1, unit=NoUnit
    StartTime_Adt: compu {phys=raw for raw 0..4294967295; unit ns}, range raw 0..4294967295, unit=ns
    StrtRqTypeStat: compu {0=STRTRQTYPESTAT_NULL, 1=STRTRQTYPESTAT_DRIVER_PRESENT, 2=STRTRQTYPESTAT_DRIVER_NOT_PRESENT; unit SED}, range raw 0..2
    TellTaleId: compu {0=TellTaleIdEnum_NONE, 1=TellTaleIdEnum_LEFT, 2=TellTaleIdEnum_RIGHT, 3=TellTaleIdEnum_BOTH}, range raw 0..3, unit=NoUnit
    Time: compu {phys=raw for raw 0..65535}, range raw 0..65535, unit=NoUnit
    TmrCntUnit32: sw-calibration-access=READ-WRITE, compu {identical; unit count} "Identical Degree Celcius", range raw 0..4294967295
    TrailerAlarmActivation: compu {0=TrailerAlarmActivation_TRAILER_ALARM_INACTIVE, 1=TrailerAlarmActivation_TRAILER_ALARM_ACTIVE}, range raw 0..1, unit=NoUnit
    TrailerAlarmFault: compu {0=TrailerAlarmFault_NO_FAULT, 1=TrailerAlarmFault_UNKNOWN_FAULT, 2=TrailerAlarmFault_TRAILER_DETECTION_FAULT, 3=TrailerAlarmFault_TRAILER_ALARM_HARDWIRED_MISCONNECTION}, range raw 0..3, unit=NoUnit
    TrailerAlarmTimer: compu {0=TrailerAlarmTimer_TRAILER_ALARM_TIMER_RUN, 1=TrailerAlarmTimer_TRAILER_ALARM_TIMER_END}, range raw 0..1, unit=NoUnit
    TrailerAlarmTrigger: compu {0=TrailerAlarmTrigger_TRAILER_ALARM_TRIGGER_INACTIVE, 1=TrailerAlarmTrigger_TRAILER_ALARM_TRIGGER_ACTIVE}, range raw 0..1, unit=NoUnit
    TrailerConnection: compu {0=TrailerConnection_TRAILER_CONNECTION_NO, 1=TrailerConnection_TRAILER_CONNECTION_YES}, range raw 0..1, unit=NoUnit
    TrailerConnectionAlarmSetting: compu {0=TrailerConnectionAlarmSetting_OFF, 1=TrailerConnectionAlarmSetting_ON}, range raw 0..1, unit=NoUnit
    TrimInhibitSettingEnum: compu {0=TrimInhibitSetting_DISABLED, 1=TrimInhibitSetting_ENABLED}, range raw 0..1, unit=NoUnit
    TrimSwitchInhibitStatusEnum: sw-calibration-access=READ-WRITE, compu {0=TrimSwitchInhibitStatus_ACTIVE, 1=TrimSwitchInhibitStatus_NON_ACTIVE}, range raw 0..1, unit=NoUnit
    TrnNtrlTowCmdActl: compu {0=TRNNTRLTOWCMDACTL_NORMAL_MODE, 1=TRNNTRLTOWCMDACTL_CAR_WASH_MODE, 2=TRNNTRLTOWCMDACTL_NEUTRAL_TOW_ENTRY, 3=TRNNTRLTOWCMDACTL_NOT_USED, else 0}, range raw 0..3, unit=NoUnit
    TurnDirectionEnum: compu {0=TurnDirection_LEFT_TURN, 1=TurnDirection_RIGHT_TURN}, range raw 0..1, unit=NoUnit
    TurnIndcnStat: compu {0=TurnIndcnStatEnum_OFF, 1=TurnIndcnStatEnum_LEFT, 2=TurnIndcnStatEnum_RIGHT}, range raw 0..2, unit=NoUnit
    TurnLightIdEnum: compu {0=TurnLightId_LEFT_FRONT, 1=TurnLightId_LEFT_REAR, 2=TurnLightId_DRIVER_SIDE, 3=TurnLightId_RIGHT_FRONT, 4=TurnLightId_RIGHT_REAR, 5=TurnLightId_PASSENGER_SIDE, 6=TurnLightId_ALL_LEFT, 7=TurnLightId_ALL_RIGHT, 8=TurnLightId_ALL, 9=TurnLightId_LEFT_TRAILER, 10=TurnLightId_RIGHT_TRAILER, 11=TurnLightId_LEFT_FRONT_FENDER, 12=TurnLightId_RIGHT_FRONT_FENDER}, range raw 0..12, unit=NoUnit
    uint16
    uint32
    uint8: sw-calibration-access=READ-WRITE, compu {phys=raw for raw 0..255}, range raw 0..255  # Updated name from Uint8 to uint8 and added compu method based on ECU extract data type
    UseCaseId: compu {phys=raw for raw 0..4294967295}, range raw 0..4294967295, unit=NoUnit
    UserSelRange: compu {phys=raw*0.01 for raw 0..65535; unit km}, range raw 0..65535, unit=km
    VehicleAreaEnum: sw-calibration-access=READ-WRITE, compu {0=VehicleArea_ALL, 1=VehicleArea_CARGO, 2=VehicleArea_CABIN}, range raw 0..2, unit=NoUnit
    VehPwMdeStat: sw-calibration-access=READ-WRITE, compu {2=VPM20, 1=VPM10, 0=NOT_USED1, 4=VPM40, 5=VPM50, 6=VPM60, 7=VPM70, 3=NOT_USED2; unit SED} "VehPowerMode_Stat", range raw 0..7
    VehPwMdeStatQlfrEnum: compu {1=VehPwMdeStatQlfr_NO_DATA_EXISTS, 2=VehPwMdeStatQlfr_PENDING, 3=VehPwMdeStatQlfr_OK, 0=VehPwMdeStatQlfr_FAULT}, range raw 0..3
    VSUActvtyStat: compu {0=VSUActvtyStat_IDLE, 1=VSUActvtyStat_SYNCING, 2=VSUActvtyStat_VEHICLE_PACKAGE_TRANSFERRING, 3=VSUActvtyStat_SOFTWARE_PACKAGE_TRANSFERRING, 4=VSUActvtyStat_PROCESSING, 5=VSUActvtyStat_ACTIVATION_PENDING, 6=VSUActvtyStat_ACTIVATING, else 0}, range raw 0..6, unit=NoUnit
    VSUInhbtStatType: compu {0=VSUInhbtStat_VSU_NO_INHIBIT, 1=VSUInhbtStat_VSU_INHIBIT, else 0}, range raw 0..1, unit=NoUnit
    WarningTypeEnum: compu {0=WarningTypeEnum_SAFETY, 1=WarningTypeEnum_HAZARD, 2=WarningTypeEnum_THEFT_ALARM, 3=WarningTypeEnum_OTHER}, range raw 0..3, unit=NoUnit
  11 x application record data type, all with category=STRUCTURE:
    ClimateAirflwSettingStrct
      5 x application record element, all with category=VALUE:
        ClimtZnID: type=ClimtZnId
        Spprtd: type=Spprtd
        ClimtAirFlowMdeStat: type=ClimtMdeStat
        ClimtAirFlowPct: type=ClimtSpdLvl
        ClimtAirFlowLvl: type=ClimtSpdLvl
    customTimeConfigStrct
      application record element DutyCycle: category=VALUE, type=uint8
      application record element CycleTime: category=VALUE, type=uint32
      application record element PauseTime: category=VALUE, type=uint32
    exteriorLightStatusStrct
      5 x application record element:
        lightPosition: category=VALUE, type=LightPositionEnum
        lightPurpose: category=VALUE, type=LightPurposeEnum
        lightActuationStatus: category=VALUE, type=ExteriorLightActuationStatus
        lightHealthStatus: category=VALUE, type=ExteriorLightHealth
        lightPresent: category=BOOLEAN, type=boolean
    GlobalStartTime
      5 x application record element, all with category=VALUE, type=Integer:
        hour
        minutes
        seconds
        MiliSeconds
        MicroSeconds
    IntrusionInclinationCapabilityStrct
      4 x application record element, all with category=VALUE, type=boolean:
        CSMSensorAvailable
        RearIntrusionSensorAvailable
        IntrusionSensorAvailable
        InclinationSensorAvailable
    IntrusionInclinationStatusStrct
      4 x application record element, all with category=VALUE:
        SensorId: type=SensorIdEnum
        SensorState: type=SensorStateEnum
        SensorModuleHealthStat: type=SensorModuleHealthEnum
        SensorTriggeredData: type=SensorTriggeredDataEnum
    RearIntrusionStatusStrct
      application record element RearIntrusionState: category=VALUE, type=SensorStateEnum
      application record element SensorModuleHealth: category=VALUE, type=SensorModuleHealthEnum
      application record element SensorTriggeredData: category=VALUE, type=SensorTriggeredDataEnum
    SounderStatusStrct
      application record element SoundActuationStatus: category=VALUE, type=SounderActuationStatusEnum
      application record element SounderHealthStatus: category=VALUE, type=SounderHealthEnum
      application record element SounderPresent: category=VALUE, type=boolean
    TellTaleActStrct
      application record element TellTaleActn: category=VALUE, type=ExteriorLightOnOff
      application record element TellTaleId: category=VALUE, type=TellTaleId
    VehPwMdeStatGrp
      application record element VehPwMdeStat: category=VALUE, type=VehPwMdeStat
      application record element VehPwMdeStatQlfr: category=VALUE, type=VehPwMdeStatQlfrEnum
    VSUInhbtStat
      application record element VSUInhbtStat: category=VALUE, type=VSUInhbtStatType
package /DataTypes/BaseTypes
  sw addr method CODE_QM: memory-allocation-keyword-policy=ADDR-METHOD-SHORT-NAME, section-type=CODE
  sw addr method VAR: memory-allocation-keyword-policy=ADDR-METHOD-SHORT-NAME, section-type=VAR
package /DataTypes/CompuMethods
  compu method LightPositionEnum: 0=LightPositionEnum_LEFT_FRONT, 1=LightPositionEnum_RIGHT_FRONT, 2=LightPositionEnum_LEFT_REAR, 3=LightPositionEnum_RIGHT_REAR, 4=LightPositionEnum_LEFT_SIDE, 5=LightPositionEnum_RIGHT_SIDE, 6=LightPositionEnum_LEFT_TRAILER_REAR, 7=LightPositionEnum_RIGHT_TRAILER_REAR, 8=LightPositionEnum_LEFT_SIDE_FRONT, 9=LightPositionEnum_RIGHT_SIDE_FRONT, 10=LightPositionEnum_CENTER_HIGH_MOUNT, 11=LightPositionEnum_DRIVER_DOOR, 12=LightPositionEnum_PASSENGER_DOOR, 13=LightPositionEnum_DRIVER_REAR_DOOR, 14=LightPositionEnum_PASSENGER_REAR_DOOR, 15=LightPositionEnum_CENTER_FRONT, 16=LightPositionEnum_CENTER_REAR, 17=LightPositionEnum_TRUCK_BED, 18=LightPositionEnum_ROOF, 19=LightPositionEnum_TRAILER_REAR, 20=LightPositionEnum_RIGHT_SIDE_REAR, 21=LightPositionEnum_LEFT_SIDE_REAR
  compu method LightPurposeEnum: 0=LightPurposeEnum_TURN_INDICATION, 1=LightPurposeEnum_BRAKE_INDICATION, 2=LightPurposeEnum_LOW_BEAM, 3=LightPurposeEnum_HIGH_BEAM, 4=LightPurposeEnum_REVERSE_INDICATION, 5=LightPurposeEnum_POSITION_PARK, 6=LightPurposeEnum_LICENSE, 7=LightPurposeEnum_SIDE_MARKER, 8=LightPurposeEnum_FOG, 9=LightPurposeEnum_DAY_TIME_RUNNING, 10=LightPurposeEnum_CORNERING, 11=LightPurposeEnum_AUX_GRILL, 12=LightPurposeEnum_MIRROR_SPOT, 13=LightPurposeEnum_REAR_CHASE, 14=LightPurposeEnum_ROCK_CRAWL, 15=LightPurposeEnum_ROOF_BAR, 16=LightPurposeEnum_BED, 17=LightPurposeEnum_DOWNLIGHTER, 18=LightPurposeEnum_FORWARD_SPOT, 19=LightPurposeEnum_TRAILER_ASSIST, 20=LightPurposeEnum_DOOR_HANDLE, 21=LightPurposeEnum_KEYPAD, 22=LightPurposeEnum_PERIMETER, 23=LightPurposeEnum_PUDDLE, 24=LightPurposeEnum_RUN_BOARD, 25=LightPurposeEnum_STATIC_BENDING, 26=LightPurpose_LOAD_INDICATOR, 27=LightPurposeEnum_FRONT_LIGHT_BAR, 28=LightPurposeEnum_BADGE, 29=LightPurposeEnum_LIT_GRILLE, 30=LightPurposeEnum_AUTONOMOUS_INTENT, 31=LightPurposeEnum_DYNAMIC_BENDING
  compu method PerimeterAlrmStat: 0=PerimeterAlrmStat_DISARMED, 1=PerimeterAlrmStat_PREARMED, 2=PerimeterAlrmStat_ARMED, 3=PerimeterAlrmStat_ACTIVATED, else 0
  compu method ReducedGuard: 0=ReducedGuard_NULL, 1=ReducedGuard_OFF, 2=ReducedGuard_ON, 3=ReducedGuard_PERSISTENTON, else 0
package /DataTypes/ImplementationDataTypes
  33 x impl type:
    ClimateAirflwSettingArr: category=ARRAY
      element ClimateAirflwSettingPtr: array-size=19, array-size-semantics=FIXED-SIZE, implementation-data-type=ClimateAirflwSettingStrct
    ClimateAirflwSettingStrct: category=STRUCTURE
      5 x element, all with category=VALUE:
        ClimtZnID: base-type=uint8
        Spprtd: base-type=boolean, range raw 0..1  # Boolean has the value space required to support the mathematical concept of binary-valued logic: {true, false}.
        ClimtAirFlowMdeStat: base-type=boolean, range raw 0..1  # Boolean has the value space required to support the mathematical concept of binary-valued logic: {true, false}.
        ClimtAirFlowPct: base-type=uint8
        ClimtAirFlowLvl: base-type=uint8
    customTimeConfigStrct: category=STRUCTURE
      element DutyCycle: implementation-data-type=uint8
      element CycleTime: implementation-data-type=uint32
      element PauseTime: implementation-data-type=uint32
    DoorAjarStatusArray: category=ARRAY
      element DoorAjarStatusArray: array-size=10, array-size-semantics=FIXED-SIZE, implementation-data-type=uint8
    DoorCinchStatusArray: category=ARRAY
      element DoorCinchStatusArray: array-size=10, array-size-semantics=FIXED-SIZE, implementation-data-type=uint8
    DoorFullOpenStatusArray: category=ARRAY
      element DoorFullOpenStatusArray: array-size=10, array-size-semantics=FIXED-SIZE, implementation-data-type=uint8
    DoorOffStatusArray: category=ARRAY
      element DoorOffStatusArray: array-size=10, array-size-semantics=FIXED-SIZE, implementation-data-type=uint8
    DoorOpenOperationStatusArray: category=ARRAY
      element DoorOpenOperationStatusArray: array-size=10, array-size-semantics=FIXED-SIZE, implementation-data-type=uint8
    DoorServiceCapabilityArray: category=ARRAY
      element DoorServiceCapabilityArray: array-size=10, array-size-semantics=FIXED-SIZE, implementation-data-type=uint8
    ExteriorDoorHandleButtonStatusArray: category=ARRAY
      element ExteriorDoorHandleButtonStatusArray: array-size=10, array-size-semantics=FIXED-SIZE, implementation-data-type=uint8
    ExteriorDoorHandleStatusArray: category=ARRAY
      element ExteriorDoorHandleStatusArray: array-size=10, array-size-semantics=FIXED-SIZE, implementation-data-type=uint8
    exteriorLightStatusStrct: category=STRUCTURE
      5 x element, all with category=TYPE_REFERENCE:
        lightPosition: implementation-data-type=uint8
        lightPurpose: implementation-data-type=uint8
        lightActuationStatus: implementation-data-type=uint8
        lightHealthStatus: implementation-data-type=uint8
        lightPresent: range raw 0..1, implementation-data-type=boolean
    ExteriorSideDoorCloseLockSwitchStatusArray: category=ARRAY
      element ExteriorSideDoorCloseLockSwitchStatusArray: array-size=6, array-size-semantics=FIXED-SIZE, implementation-data-type=uint8
    ExteriorSideDoorUnlockReleaseSwitchStatusArray: category=ARRAY
      element ExteriorSideDoorUnlockReleaseSwitchStatusArray: array-size=6, array-size-semantics=FIXED-SIZE, implementation-data-type=uint8
    GlobalStartTime: category=STRUCTURE
      5 x element, all with category=TYPE_REFERENCE, implementation-data-type=uint8:
        hour
        minutes
        seconds
        MiliSeconds
        MicroSeconds
    InteriorDoorHandleButtonStatusArray: category=ARRAY
      element InteriorDoorHandleButtonStatusArray: array-size=10, array-size-semantics=FIXED-SIZE, implementation-data-type=uint8
    InteriorDoorHandleStatusArray: category=ARRAY
      element InteriorDoorHandleStatusArray: array-size=10, array-size-semantics=FIXED-SIZE, implementation-data-type=uint8
    InteriorSideDoorReleaseSwitchStatusArray: category=ARRAY
      element InteriorSideDoorReleaseSwitchStatusArray: array-size=6, array-size-semantics=FIXED-SIZE, implementation-data-type=uint8
    IntrusionInclinationCapabilityArr: category=ARRAY
      element IntrusionInclinationCapabilityArr: array-size=4, array-size-semantics=FIXED-SIZE, implementation-data-type=IntrusionInclinationCapabilityStrct
    IntrusionInclinationCapabilityStrct: category=STRUCTURE
      4 x element, all with category=TYPE_REFERENCE, implementation-data-type=boolean:
        CSMSensorAvailable
        RearIntrusionSensorAvailable
        IntrusionSensorAvailable
        InclinationSensorAvailable
    IntrusionInclinationStatusArr: category=ARRAY
      element IntrusionInclinationStatusArr: array-size=2, array-size-semantics=FIXED-SIZE, implementation-data-type=IntrusionInclinationStatusStrct
    IntrusionInclinationStatusStrct: category=STRUCTURE
      4 x element, all with category=TYPE_REFERENCE, implementation-data-type=uint8:
        SensorId
        SensorState
        SensorModuleHealthStat
        SensorTriggeredData
    LatchPositionStatusArray: category=ARRAY
      element LatchPositionStatusArray: array-size=10, array-size-semantics=FIXED-SIZE, implementation-data-type=uint8
    OpenCloseCustomizationStatusArray: category=ARRAY
      element OpenCloseCustomizationStatusArray: array-size=10, array-size-semantics=FIXED-SIZE, implementation-data-type=uint8
    PerimeterAlarmEvStackArray: category=ARRAY
      element uint8: category=VALUE, array-size=4, array-size-semantics=FIXED-SIZE, base-type=uint8
    PerimeterAlarmTmStackArray: category=ARRAY
      element uint32: category=VALUE, array-size=4, array-size-semantics=FIXED-SIZE, base-type=uint32
    RearIntrusionStatusStrct: category=STRUCTURE
      element RearIntrusionState: implementation-data-type=uint8
      element SensorModuleHealth: implementation-data-type=uint8
      element SensorTriggeredData: implementation-data-type=uint8
    SounderStatusArr: category=ARRAY
      element SounderStatusArr: array-size=4, array-size-semantics=FIXED-SIZE, implementation-data-type=SounderStatusStrct
    SounderStatusStrct: category=STRUCTURE
      element SoundActuationStatus: implementation-data-type=uint8
      element SounderHealthStatus: implementation-data-type=uint8
      element SounderPresent: implementation-data-type=boolean
    TellTaleActStrct: category=STRUCTURE
      element TellTaleActn: implementation-data-type=boolean
      element TellTaleId: implementation-data-type=uint8
    TurnLightStatusArray: category=ARRAY
      element TurnLightStatusArray: array-size=10, array-size-semantics=FIXED-SIZE, implementation-data-type=exteriorLightStatusStrct
    VehPwMdeStatGrp: category=STRUCTURE
      element VehPwMdeStat: implementation-data-type=uint8
      element VehPwMdeStatQlfr: implementation-data-type=uint8
    VSUInhbtStat: category=STRUCTURE
      element VSUInhbtStat: implementation-data-type=uint8
package /DataTypes/Units
  8 x unit, all with factor-si-to-unit=1:
    count: display-name=count, offset-si-to-unit=-1
    Kilometer: display-name=km, offset-si-to-unit=0
    msec: display-name=ms, offset-si-to-unit=-1
    NoUnit: display-name=NoUnit, offset-si-to-unit=0
    NoUnit1: display-name=NoUnit, offset-si-to-unit=0
    nSec: display-name=ns, offset-si-to-unit=-1
    Percentage: display-name=%, offset-si-to-unit=0
    SED: display-name=SED, offset-si-to-unit=0
package /Interfaces
  client server interface ResourceManagerDirectInterface
    operation startUseCase: possible-error=[InvalidDuration, InvalidOperation, InvalidUseCaseId]
      arg useCaseId: type=UseCaseId, direction=IN, server-argument-impl-policy=USE-ARGUMENT-TYPE
      arg duration: type=Duration, direction=IN, server-argument-impl-policy=USE-ARGUMENT-TYPE
    operation terminateUseCase: possible-error=[InvalidOperation, InvalidUseCaseId]
      arg useCaseId: type=UseCaseId, direction=IN, server-argument-impl-policy=USE-ARGUMENT-TYPE
    error InvalidDuration: error-code=3
    error InvalidOperation: error-code=4
    error InvalidUseCaseId: error-code=1
  client server interface sounderInterface
    operation activateCustomSounder: possible-error=[sounderInterface/InvalidParameter, sounderInterface/OverriddenInsufficientPriority, sounderInterface/State, sounderInterface/UnknownError]
      4 x arg, all with direction=IN, server-argument-impl-policy=USE-ARGUMENT-TYPE:
        sounderId: type=SounderIdEnum
        repetitions: type=uint16
        timeConfig: type=customTimeConfigStrct
        activationTimeStamp: type=uint32
    operation actuateSounder: possible-error=[sounderInterface/InvalidParameter, sounderInterface/OverriddenInsufficientPriority, sounderInterface/State, sounderInterface/UnknownError]
      5 x arg, all with direction=IN, server-argument-impl-policy=USE-ARGUMENT-TYPE:
        soundPattern: type=SoundPatternEnum
        soundRequest: type=SounderRequestEnum
        repetitions: type=uint16
        pauseBetweenRepetition: type=uint16
        activationTimeStamp: type=uint32
    operation get_sounderStatus
      arg SounderStatus: type=SounderStatusArr, direction=OUT, server-argument-impl-policy=USE-ARGUMENT-TYPE
    4 x error:
      InvalidParameter: error-code=1
      OverriddenInsufficientPriority: error-code=10
      State: error-code=5
      UnknownError: error-code=2
  client server interface TurnLightServiceInterface
    5 x operation:
      get_turnLightStatus: possible-error=[TurnLightServiceInterface/InvalidParameter, TurnLightServiceInterface/UnknownError]
        arg out_argument: type=TurnLightStatusArray, direction=OUT, server-argument-impl-policy=USE-ARGUMENT-TYPE
      SomeIpmcustomControlTurnLight: possible-error=[TurnLightServiceInterface/InvalidParameter, TurnLightServiceInterface/State, TurnLightServiceInterface/UnknownError]
        8 x arg, all with direction=IN, server-argument-impl-policy=USE-ARGUMENT-TYPE:
          turnLightId: type=TurnLightIdEnum
          exteriorLightAction: type=ExteriorLightActuationStatus
          intensity: type=Intensity_Adt
          fadeSpeed: type=ExtrLghtMs
          flashOnTime: type=ExtrLghtMs
          flashOffTime: type=ExtrLghtMs
          totalFlashes: type=Integer
          flashStartTime: type=GlobalStartTime
      SomeIpmflashFeedbackLight: possible-error=[TurnLightServiceInterface/InvalidParameter, TurnLightServiceInterface/OverriddenInsufficientPriority, TurnLightServiceInterface/State, TurnLightServiceInterface/UnknownError]
        6 x arg, all with direction=IN, server-argument-impl-policy=USE-ARGUMENT-TYPE:
          flashPattern: type=FlashPatternEnum
          customOnTime: type=ExtrLghtMs
          customOffTime: type=ExtrLghtMs
          CustomNumberOfFlashes: type=Integer
          OverrideHazards: type=boolean
          OverrideTransport: type=boolean
      SomeIpmflashWarningLight: possible-error=[TurnLightServiceInterface/InvalidParameter, LightSessionNotActive, TurnLightServiceInterface/OverriddenInsufficientPriority, TurnLightServiceInterface/State, TurnLightServiceInterface/UnknownError]
        4 x arg, all with server-argument-impl-policy=USE-ARGUMENT-TYPE:
          WarningLightRequest: type=ExteriorLightOnOff, direction=IN
          WarningType: type=WarningTypeEnum, direction=IN
          WarningLightSessionIdIn: type=Integer, direction=IN
          WarningLightSessionIdOut: type=Integer, direction=OUT
      SomeIpmindicateTurn: possible-error=[TurnLightServiceInterface/InvalidParameter, TurnLightServiceInterface/OverriddenInsufficientPriority, TurnLightServiceInterface/State, TurnLightServiceInterface/UnknownError]
        4 x arg, all with direction=IN, server-argument-impl-policy=USE-ARGUMENT-TYPE:
          turnDirection: type=TurnDirectionEnum
          turnLightRequest: type=ExteriorLightOnOff
          limitNumberOfFlashes: type=Integer
          turnIndicationPriority: type=Priority
    5 x error:
      InvalidParameter: error-code=1
      LightSessionNotActive: error-code=63
      OverriddenInsufficientPriority: error-code=10
      State: error-code=5
      UnknownError: error-code=2
  4 x nv data interface:
    NvmAlarmSoundCfgM2
      nv-datas:
        data AlarmSoundCfg: type=AlarmSoundCfg
    NvmHornSoundCfgM2
      nv-datas:
        data HornSoundCfg: type=boolean
    NvmPAMaxActivationCfgM2
      nv-datas:
        data PAMaxActivationCfg: type=uint8
    NvmPerimeterAlarmCfgM2
      nv-datas:
        data PerimeterAlarmCfg: type=boolean
  20 x sender receiver interface:
    LifeCycMdeDActl: invalidation-policy{data-element=LifeCycMdeDActl/Val, handle-invalid=DONT-INVALIDATE}
      data Val: type=LifeCycMdeDActl
    on_changeIntrusionInclinationStatusInterface: invalidation-policy{data-element=on_changeIntrusionInclinationStatus, handle-invalid=DONT-INVALIDATE}
      data on_changeIntrusionInclinationStatus: type=IntrusionInclinationStatusArr
    onChange_climateAirflwSettingInterface: invalidation-policy{data-element=onChange_climateAirflwSetting, handle-invalid=DONT-INVALIDATE}
      data onChange_climateAirflwSetting: type=ClimateAirflwSettingArr
    onChange_doorAjarStatusInterface: invalidation-policy{data-element=onChange_doorAjarStatus, handle-invalid=DONT-INVALIDATE}
      data onChange_doorAjarStatus: type=DoorAjarStatusArray
    onChange_exteriorDoorHandleStatusInterface: invalidation-policy{data-element=onChange_exteriorDoorHandleStatus, handle-invalid=DONT-INVALIDATE}
      data onChange_exteriorDoorHandleStatus: type=ExteriorDoorHandleStatusArray
    onChange_exteriorLockEventCountInterface: invalidation-policy{data-element=onChange_exteriorLockEventCount, handle-invalid=DONT-INVALIDATE}
      data onChange_exteriorLockEventCount: type=Integer
    onChange_exteriorVehicleLockStatusInterface: invalidation-policy{data-element=onChange_exteriorVehicleLockStatus, handle-invalid=DONT-INVALIDATE}
      data onChange_exteriorVehicleLockStatus: type=ExteriorVehicleLockStatusEnum
    onChange_infiniteTimerStatusInterface: invalidation-policy{data-element=onChange_infiniteTimerStatus, handle-invalid=DONT-INVALIDATE}
      data onChange_infiniteTimerStatus: type=RequestStatusType
    onChange_lastLockUnlockRequestorInterface: invalidation-policy{data-element=onChange_lastLockUnlockRequestor, handle-invalid=DONT-INVALIDATE}
      data onChange_lastLockUnlockRequestor: type=RequestorTypeClassEnum
    OnOffNull2: invalidation-policy{data-element=OnOffNull2/Val, handle-invalid=DONT-INVALIDATE}
      data Val: type=OnOffNull2
    PerimeterAlarmEvStackArray: invalidation-policy{data-element=PerimeterAlarmEvStackArray/DeVal, handle-invalid=DONT-INVALIDATE}
      data DeVal: type=PerimeterAlarmEvStackArray
    PerimeterAlarmTmStackArray: invalidation-policy{data-element=PerimeterAlarmTmStackArray/DeVal, handle-invalid=DONT-INVALIDATE}
      data DeVal: type=PerimeterAlarmTmStackArray
    PerimeterAlrmStat: invalidation-policy{data-element=PerimeterAlrmStat/Val, handle-invalid=DONT-INVALIDATE}
      data Val: type=PerimeterAlrmStat
    PrmtrAlrmEvntDStat2: invalidation-policy{data-element=PrmtrAlrmEvntDStat2/Val, handle-invalid=DONT-INVALIDATE}
      data Val: type=PrmtrAlrmEvntDStat2
    ReducedGuard: invalidation-policy{data-element=ReducedGuard/Val, handle-invalid=DONT-INVALIDATE}
      data Val: type=ReducedGuard
    TmrSecCnt: invalidation-policy{data-element=TmrSecCnt/DeVal, handle-invalid=DONT-INVALIDATE}
      data DeVal: sw-addr-method=VAR, type=TmrCntUnit32
    TrnNtrlTowCmdActl: invalidation-policy{data-element=TrnNtrlTowCmdActl/Val, handle-invalid=DONT-INVALIDATE}
      data Val: type=TrnNtrlTowCmdActl
    VehPwMdeStatGrp: invalidation-policy{data-element=VehPwMdeStatGrp/Grp, handle-invalid=DONT-INVALIDATE}
      data Grp: type=VehPwMdeStatGrp
    VSUActvtyStat: invalidation-policy{data-element=VSUActvtyStat/Val, handle-invalid=DONT-INVALIDATE}
      data Val: type=VSUActvtyStat
    VSUInhbtStat: invalidation-policy{data-element=VSUInhbtStat/Grp, handle-invalid=DONT-INVALIDATE}
      data Grp: type=VSUInhbtStat
package /PortInterfaces
  client server interface IntrusionInclinationInterface
    4 x operation:
      controlIntrusionInclinationMode: possible-error=[IntrusionInclinationInterface/InvalidParameter, IntrusionInclinationInterface/State, IntrusionInclinationInterface/State, IntrusionInclinationInterface/UnknownError]
        arg intrusionInclinationId: type=IntrusionInclinationIdEnum, direction=IN, server-argument-impl-policy=USE-ARGUMENT-TYPE
        arg modeId: type=ModeIdEnum, direction=IN, server-argument-impl-policy=USE-ARGUMENT-TYPE
      get_intrusionInclinationCapability
        arg IntrusionInclinationCapability: type=IntrusionInclinationCapabilityArr, direction=OUT, server-argument-impl-policy=USE-ARGUMENT-TYPE
      get_intrusionInclinationStatus
        arg IntrusionInclinationCapability: type=IntrusionInclinationStatusArr, direction=OUT, server-argument-impl-policy=USE-ARGUMENT-TYPE
      get_rearIntrusionStatus
        arg rearIntrusionStatus: type=RearIntrusionStatusStrct, direction=OUT, server-argument-impl-policy=USE-ARGUMENT-TYPE
    error InvalidParameter: error-code=1
    error State: error-code=5
    error UnknownError: error-code=2
  4 x nv data interface:
    NvmPATrailerConnectCfgM2
      nv-datas:
        data TrailerConnectCfg: type=boolean
    NvmPerimeterAlrmStat
      nv-datas:
        data PerimeterAlrmStat: type=PerimeterAlrmStat
    NvmReducedGuard
      nv-datas:
        data ReducedGuard: type=ReducedGuard
    NvmSecurityCfgM2
      nv-datas:
        data SecurityCfg: type=SecurityCfg
package /SoftwareTypes/ComponentTypes
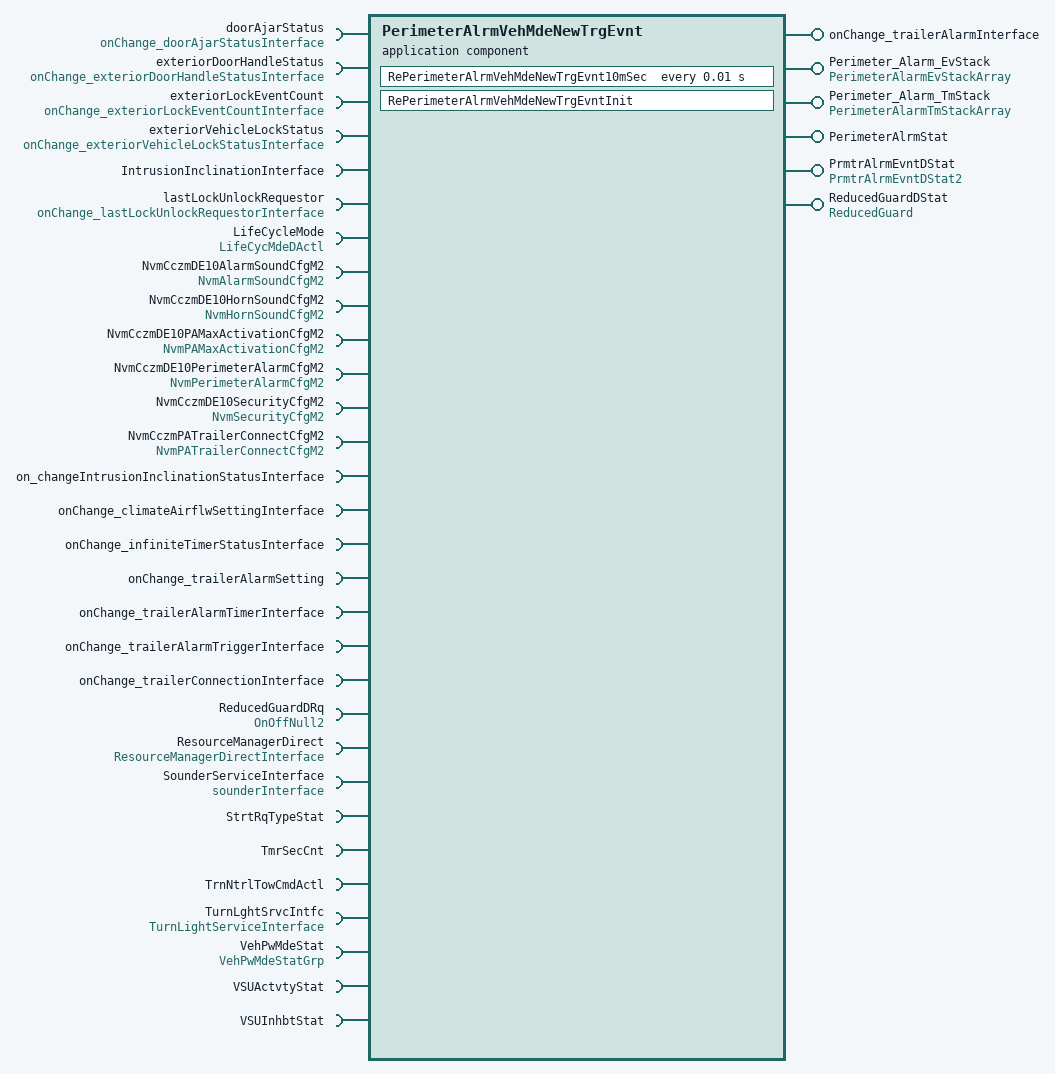
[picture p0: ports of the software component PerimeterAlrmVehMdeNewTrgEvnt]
  application sw component type PerimeterAlrmVehMdeNewTrgEvnt
    6 x provide port:
      onChange_trailerAlarmInterface: nonqueued-sender-com-spec{data-element=onChange_trailerAlarm, init-value=0}, provided-interface=onChange_trailerAlarmInterface
      Perimeter_Alarm_EvStack: nonqueued-sender-com-spec=data-element=PerimeterAlarmEvStackArray/DeVal, provided-interface=PerimeterAlarmEvStackArray
      Perimeter_Alarm_TmStack: nonqueued-sender-com-spec=data-element=PerimeterAlarmTmStackArray/DeVal, provided-interface=PerimeterAlarmTmStackArray
      PerimeterAlrmStat: nonqueued-sender-com-spec{data-element=PerimeterAlrmStat/Val, init-value=constant-reference=InitVal_PerimeterAlrmStat}, provided-interface=PerimeterAlrmStat
      PrmtrAlrmEvntDStat: nonqueued-sender-com-spec{data-element=PrmtrAlrmEvntDStat2/Val, init-value=0}, provided-interface=PrmtrAlrmEvntDStat2
      ReducedGuardDStat: nonqueued-sender-com-spec{data-element=ReducedGuard/Val, init-value=constant-reference=Init_ReducedGuardDStat}, provided-interface=ReducedGuard
    provide/require port NvmCczmAlarmsHornPerimeterAlrmStat: nv-provide-com-spec{ram-block-init-value=0, rom-block-init-value=0, variable=PerimeterAlrmStat}, nv-require-com-spec{init-value=0, variable=PerimeterAlrmStat}, provided-required-interface=NvmPerimeterAlrmStat
    provide/require port NvmCczmAlarmsHornReducedGuard: nv-provide-com-spec{ram-block-init-value=0, rom-block-init-value=0, variable=ReducedGuard}, nv-require-com-spec{init-value=0, variable=ReducedGuard}, provided-required-interface=NvmReducedGuard
    30 x require port:
      doorAjarStatus: nonqueued-receiver-com-spec{data-element=onChange_doorAjarStatus, filter=data-filter-type=ALWAYS, init-value=constant-reference=InitVal_doorAjarStatus}, required-interface=onChange_doorAjarStatusInterface
      exteriorDoorHandleStatus: nonqueued-receiver-com-spec{data-element=onChange_exteriorDoorHandleStatus, filter=data-filter-type=ALWAYS, init-value=constant-reference=InitVal_exteriorDoorHandleStatus}, required-interface=onChange_exteriorDoorHandleStatusInterface
      exteriorLockEventCount: nonqueued-receiver-com-spec{data-element=onChange_exteriorLockEventCount, filter=data-filter-type=ALWAYS, init-value=constant-reference=InitVal_exteriorLockEventCount}, required-interface=onChange_exteriorLockEventCountInterface
      exteriorVehicleLockStatus: nonqueued-receiver-com-spec{data-element=onChange_exteriorVehicleLockStatus, filter=data-filter-type=ALWAYS, init-value=constant-reference=InitVal_exteriorVehicleLockStatus}, required-interface=onChange_exteriorVehicleLockStatusInterface
      IntrusionInclinationInterface: required-interface=IntrusionInclinationInterface
        required-com-specs:
          controlIntrusionInclinationMode
          get_intrusionInclinationCapability
          get_intrusionInclinationStatus
          get_rearIntrusionStatus
      lastLockUnlockRequestor: nonqueued-receiver-com-spec{data-element=onChange_lastLockUnlockRequestor, filter=data-filter-type=ALWAYS, init-value=constant-reference=InitVal_lastLockUnlockRequestor}, required-interface=onChange_lastLockUnlockRequestorInterface
      LifeCycleMode: nonqueued-receiver-com-spec{data-element=LifeCycMdeDActl/Val, filter=data-filter-type=ALWAYS, init-value=LifeCycMdeDActl_NORMAL}, required-interface=LifeCycMdeDActl
      NvmCczmDE10AlarmSoundCfgM2: nv-require-com-spec{init-value=0, variable=AlarmSoundCfg}, required-interface=NvmAlarmSoundCfgM2
      NvmCczmDE10HornSoundCfgM2: nv-require-com-spec{init-value=1, variable=HornSoundCfg}, required-interface=NvmHornSoundCfgM2
      NvmCczmDE10PAMaxActivationCfgM2: nv-require-com-spec{init-value=10, variable=PAMaxActivationCfg}, required-interface=NvmPAMaxActivationCfgM2
      NvmCczmDE10PerimeterAlarmCfgM2: nv-require-com-spec{init-value=1, variable=PerimeterAlarmCfg}, required-interface=NvmPerimeterAlarmCfgM2
      NvmCczmDE10SecurityCfgM2: nv-require-com-spec{init-value=1, variable=SecurityCfg}, required-interface=NvmSecurityCfgM2
      NvmCczmPATrailerConnectCfgM2: nv-require-com-spec{init-value=0, variable=TrailerConnectCfg}, required-interface=NvmPATrailerConnectCfgM2
      on_changeIntrusionInclinationStatusInterface: nonqueued-receiver-com-spec{data-element=on_changeIntrusionInclinationStatus, filter=data-filter-type=ALWAYS, init-value=constant-reference=InitValue_IntrusionInclinationStatus}, required-interface=on_changeIntrusionInclinationStatusInterface
      onChange_climateAirflwSettingInterface: nonqueued-receiver-com-spec{data-element=onChange_climateAirflwSetting, filter=data-filter-type=ALWAYS, init-value=19 x fields=[ClimtZnID:0, Spprtd:0, ClimtAirFlowMdeStat:0, ClimtAirFlowPct:0, ClimtAirFlowLvl:0]}, required-interface=onChange_climateAirflwSettingInterface
      onChange_infiniteTimerStatusInterface: nonqueued-receiver-com-spec{data-element=onChange_infiniteTimerStatus, filter=data-filter-type=ALWAYS, init-value=constant-reference=Init_RequestStatusType}, required-interface=onChange_infiniteTimerStatusInterface
      onChange_trailerAlarmSetting: nonqueued-receiver-com-spec{data-element=onChange_trailerAlarmSetting, filter=data-filter-type=ALWAYS, init-value=0}, required-interface=onChange_trailerAlarmSetting
      onChange_trailerAlarmTimerInterface: nonqueued-receiver-com-spec{data-element=onChange_trailerAlarmTimer, filter=data-filter-type=ALWAYS, init-value=0}, required-interface=onChange_trailerAlarmTimerInterface
      onChange_trailerAlarmTriggerInterface: nonqueued-receiver-com-spec{data-element=onChange_trailerAlarmTrigger, filter=data-filter-type=ALWAYS, init-value=0}, required-interface=onChange_trailerAlarmTriggerInterface
      onChange_trailerConnectionInterface: nonqueued-receiver-com-spec{data-element=onChange_trailerConnection, filter=data-filter-type=ALWAYS, init-value=0}, required-interface=onChange_trailerConnectionInterface
      ReducedGuardDRq: nonqueued-receiver-com-spec{data-element=OnOffNull2/Val, filter=data-filter-type=ALWAYS, init-value=constant-reference=Init_OnOffNull2}, required-interface=OnOffNull2
      ResourceManagerDirect: required-com-specs=[startUseCase, terminateUseCase], required-interface=ResourceManagerDirectInterface
      SounderServiceInterface: required-com-specs=[activateCustomSounder, actuateSounder, get_sounderStatus], required-interface=sounderInterface
      StrtRqTypeStat: nonqueued-receiver-com-spec{data-element=StrtRqTypeStat/Val, filter=data-filter-type=ALWAYS, init-value=0}, required-interface=StrtRqTypeStat
      TmrSecCnt: nonqueued-receiver-com-spec{data-element=TmrSecCnt/DeVal, filter=data-filter-type=ALWAYS, init-value=0}, required-interface=TmrSecCnt
      TrnNtrlTowCmdActl: nonqueued-receiver-com-spec{data-element=TrnNtrlTowCmdActl/Val, filter=data-filter-type=ALWAYS, init-value=constant-reference=Init_TrnNtrlTowCmdActl}, required-interface=TrnNtrlTowCmdActl
      TurnLghtSrvcIntfc: required-interface=TurnLightServiceInterface
        required-com-specs:
          get_turnLightStatus
          SomeIpmcustomControlTurnLight
          SomeIpmflashFeedbackLight
          SomeIpmflashWarningLight
          SomeIpmindicateTurn
      VehPwMdeStat: nonqueued-receiver-com-spec{data-element=VehPwMdeStatGrp/Grp, filter=data-filter-type=ALWAYS, init-value=constant-reference=InitVal_VehPwMdeStatGrp}, required-interface=VehPwMdeStatGrp
      VSUActvtyStat: nonqueued-receiver-com-spec{data-element=VSUActvtyStat/Val, filter=data-filter-type=ALWAYS, init-value=constant-reference=InitVal_VSUActvtyStat}, required-interface=VSUActvtyStat
      VSUInhbtStat: nonqueued-receiver-com-spec{data-element=VSUInhbtStat/Grp, filter=data-filter-type=ALWAYS, init-value=constant-reference=InitVal_VSUInhbtStat}, required-interface=VSUInhbtStat
    behavior PerimeterAlrmVehMdeNewTrgEvnt_1_ib: data-type-mapping=[PerimeterAlrmVehMdeNewTrgEvnt, SounderSrvc, Timer, DataTypeMappingSet_AutoVehicleShutdownServiceProvider, DataTypeMappingSet_PerimeterAntiTheftAlarmFeatureApp, DataTypeMappingSet_PerimeterAntiTheftAlarmFeatureAppASILB, DataTypeMappingSet_SounderServiceProvider, DataTypeMappingSet_IntrusionInclinationServiceProvider, DataTypeMappingSet_TurnLightServiceProvider, DataTypeMappingSet_DoorService, DataTypeMappingSet_TrailerAlarmServiceProvider, DataTypeMappingSet_TrailerAlarmServiceConsumer, DataTypeMappingSet_TrailerConnectionAlarmServiceProvider, DataTypeMappingSet_StrtUpStopArbitrator], handle-termination-and-restart=NO-SUPPORT
      timing event EvPerimeterAlrmVehMdeNewTrgEvnt10mSec: start-on-event=RePerimeterAlrmVehMdeNewTrgEvnt10mSec, period=0.01
      init event EvPerimeterAlrmVehMdeNewTrgEvntInit: start-on-event=RePerimeterAlrmVehMdeNewTrgEvntInit
      runnable RePerimeterAlrmVehMdeNewTrgEvnt10mSec: sw-addr-method=CODE_QM
        data-receive-point-by-arguments:
          28 x access:
            doorAjarStatus: accessed-variable=doorAjarStatus.onChange_doorAjarStatus
            exteriorDoorHandleStatus: accessed-variable=exteriorDoorHandleStatus.onChange_exteriorDoorHandleStatus
            exteriorLockEventCount: accessed-variable=exteriorLockEventCount.onChange_exteriorLockEventCount
            exteriorVehicleLockStatus: accessed-variable=exteriorVehicleLockStatus.onChange_exteriorVehicleLockStatus
            lastLockUnlockRequestor: accessed-variable=lastLockUnlockRequestor.onChange_lastLockUnlockRequestor
            LifeCycMdeDActl: accessed-variable=LifeCycleMode.Val
            NvmrAlarmSoundCfgM2: accessed-variable=NvmCczmDE10AlarmSoundCfgM2.AlarmSoundCfg
            NvmrHornSoundCfgM2: accessed-variable=NvmCczmDE10HornSoundCfgM2.HornSoundCfg
            NvmrPerimeterAlarmCfgM2: accessed-variable=NvmCczmDE10PerimeterAlarmCfgM2.PerimeterAlarmCfg
            REC_NVM_PerimeterAlrmStat_NVM_PerimeterAlrmStat: accessed-variable=NvmCczmAlarmsHornPerimeterAlrmStat.PerimeterAlrmStat
            REC_NVM_ReducedGuard_NVM_ReducedGuard: accessed-variable=NvmCczmAlarmsHornReducedGuard.ReducedGuard
            REC_NvmCczmPATrailerConnectCfgM2_TrailerConnectCfg: accessed-variable=NvmCczmPATrailerConnectCfgM2.TrailerConnectCfg
            REC_on_changeIntrusionInclinationStatusInterface_on_changeIntrusionInclinationStatus: accessed-variable=on_changeIntrusionInclinationStatusInterface.on_changeIntrusionInclinationStatus
            REC_onChange_climateAirflwSettingInterface_onChange_climateAirflwSetting: accessed-variable=onChange_climateAirflwSettingInterface.onChange_climateAirflwSetting
            REC_onChange_infiniteTimerStatusInterface_onChange_infiniteTimerStatus: accessed-variable=onChange_infiniteTimerStatusInterface.onChange_infiniteTimerStatus
            REC_onChange_trailerAlarmSetting_onChange_trailerAlarmSetting: accessed-variable=onChange_trailerAlarmSetting.onChange_trailerAlarmSetting
            REC_onChange_trailerAlarmTimerInterface_onChange_trailerAlarmTimer: accessed-variable=onChange_trailerAlarmTimerInterface.onChange_trailerAlarmTimer
            REC_onChange_trailerAlarmTriggerInterface_onChange_trailerAlarmTrigger: accessed-variable=onChange_trailerAlarmTriggerInterface.onChange_trailerAlarmTrigger
            REC_onChange_trailerConnectionInterface_onChange_trailerConnection: accessed-variable=onChange_trailerConnectionInterface.onChange_trailerConnection
            REC_PAMaxActivationCfgM2_NvdVal: accessed-variable=NvmCczmDE10PAMaxActivationCfgM2.PAMaxActivationCfg
            REC_ReducedGuardDRq_Val: accessed-variable=ReducedGuardDRq.Val
            REC_SecurityCfgM2_SecurityCfg: accessed-variable=NvmCczmDE10SecurityCfgM2.SecurityCfg
            REC_StrtRqTypeStat_Val: accessed-variable=StrtRqTypeStat.Val
            REC_TrnNtrlTowCmdActl_Val: accessed-variable=TrnNtrlTowCmdActl.Val
            REC_VSUActvtyStat_Val: accessed-variable=VSUActvtyStat.Val
            REC_VSUInhbtStat_Grp: accessed-variable=VSUInhbtStat.Grp
            TmrSecCnt: accessed-variable=TmrSecCnt.DeVal
            VehPwrModStat: accessed-variable=VehPwMdeStat.Grp
        data-send-points:
          8 x access:
            Perimeter_Alarm_EvStack: accessed-variable=Perimeter_Alarm_EvStack.DeVal
            Perimeter_Alarm_TmStack: accessed-variable=Perimeter_Alarm_TmStack.DeVal
            PerimeterAlrmStat: accessed-variable=PerimeterAlrmStat.Val
            PrmtrAlrmEvntDStat: accessed-variable=PrmtrAlrmEvntDStat.Val
            SEND_NVM_PerimeterAlrmStat_NVM_PerimeterAlrmStat: accessed-variable=NvmCczmAlarmsHornPerimeterAlrmStat.PerimeterAlrmStat
            SEND_NVM_ReducedGuard_NVM_ReducedGuard: accessed-variable=NvmCczmAlarmsHornReducedGuard.ReducedGuard
            SEND_onChange_trailerAlarmInterface_onChange_trailerAlarm: accessed-variable=onChange_trailerAlarmInterface.onChange_trailerAlarm
            SEND_ReducedGuardDStat_Val: accessed-variable=ReducedGuardDStat.Val
        5 x sync call, all with timeout=0:
          actuateSounder: operation=SounderServiceInterface.actuateSounder
          SC_IntrusionInclinationInterface_controlIntrusionInclinationMode: operation=IntrusionInclinationInterface.controlIntrusionInclinationMode
          SomeIpmflashWarningLight: operation=TurnLghtSrvcIntfc.SomeIpmflashWarningLight
          startUseCase: operation=ResourceManagerDirect.startUseCase
          terminateUseCase: operation=ResourceManagerDirect.terminateUseCase
      runnable RePerimeterAlrmVehMdeNewTrgEvntInit: sw-addr-method=CODE_QM
  swc implementation PerimeterAlrmVehMdeNewTrgEvnt_Implementation: behavior=PerimeterAlrmVehMdeNewTrgEvnt_1_ib
    code-descriptors:
      code Default: artifact-descriptors=autosar-engineering-object=category=SWSRC
package /SoftwareTypes/Interfaces
  6 x sender receiver interface:
    onChange_trailerAlarmInterface: invalidation-policy{data-element=onChange_trailerAlarm, handle-invalid=DONT-INVALIDATE}
      data onChange_trailerAlarm: type=TrailerAlarmActivation
    onChange_trailerAlarmSetting: invalidation-policy{data-element=onChange_trailerAlarmSetting, handle-invalid=DONT-INVALIDATE}
      data onChange_trailerAlarmSetting: type=TrailerConnectionAlarmSetting
    onChange_trailerAlarmTimerInterface: invalidation-policy{data-element=onChange_trailerAlarmTimer, handle-invalid=DONT-INVALIDATE}
      data onChange_trailerAlarmTimer: type=TrailerAlarmTimer
    onChange_trailerAlarmTriggerInterface: invalidation-policy{data-element=onChange_trailerAlarmTrigger, handle-invalid=DONT-INVALIDATE}
      data onChange_trailerAlarmTrigger: type=TrailerAlarmTrigger
    onChange_trailerConnectionInterface: invalidation-policy{data-element=onChange_trailerConnection, handle-invalid=DONT-INVALIDATE}
      data onChange_trailerConnection: type=TrailerConnection
    StrtRqTypeStat: invalidation-policy{data-element=StrtRqTypeStat/Val, handle-invalid=DONT-INVALIDATE}
      data Val: sw-calibration-access=READ-ONLY, type=StrtRqTypeStat
